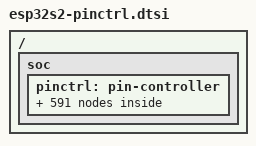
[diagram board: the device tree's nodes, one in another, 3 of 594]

/*
 * Copyright (c) 2022 Espressif Systems (Shanghai) Co., Ltd.
 *
 * SPDX-License-Identifier: Apache-2.0
 *
 * NOTE: Autogenerated file using esp_genpinctrl.py
 */

#include <dt-bindings/pinctrl/esp32-pinctrl.h>
#include <dt-bindings/pinctrl/esp32s2-gpio-sigmap.h>

/ {
	soc {
		pinctrl: pin-controller {

			/* I2C0's SCL pin states */
			i2c0_scl_gpio0: i2c0_scl_gpio0 {
				pinmux = <ESP32_PINMUX(0, ESP_I2CEXT0_SCL_IN, ESP_I2CEXT0_SCL_OUT)>;
				bias-pull-up;
				drive-open-drain;
				input-enable;
				output-high;
			};

			i2c0_scl_gpio1: i2c0_scl_gpio1 {
				pinmux = <ESP32_PINMUX(1, ESP_I2CEXT0_SCL_IN, ESP_I2CEXT0_SCL_OUT)>;
				bias-pull-up;
				drive-open-drain;
				input-enable;
				output-high;
			};

			i2c0_scl_gpio2: i2c0_scl_gpio2 {
				pinmux = <ESP32_PINMUX(2, ESP_I2CEXT0_SCL_IN, ESP_I2CEXT0_SCL_OUT)>;
				bias-pull-up;
				drive-open-drain;
				input-enable;
				output-high;
			};

			i2c0_scl_gpio3: i2c0_scl_gpio3 {
				pinmux = <ESP32_PINMUX(3, ESP_I2CEXT0_SCL_IN, ESP_I2CEXT0_SCL_OUT)>;
				bias-pull-up;
				drive-open-drain;
				input-enable;
				output-high;
			};

			i2c0_scl_gpio4: i2c0_scl_gpio4 {
				pinmux = <ESP32_PINMUX(4, ESP_I2CEXT0_SCL_IN, ESP_I2CEXT0_SCL_OUT)>;
				bias-pull-up;
				drive-open-drain;
				input-enable;
				output-high;
			};

			i2c0_scl_gpio5: i2c0_scl_gpio5 {
				pinmux = <ESP32_PINMUX(5, ESP_I2CEXT0_SCL_IN, ESP_I2CEXT0_SCL_OUT)>;
				bias-pull-up;
				drive-open-drain;
				input-enable;
				output-high;
			};

			i2c0_scl_gpio6: i2c0_scl_gpio6 {
				pinmux = <ESP32_PINMUX(6, ESP_I2CEXT0_SCL_IN, ESP_I2CEXT0_SCL_OUT)>;
				bias-pull-up;
				drive-open-drain;
				input-enable;
				output-high;
			};

			i2c0_scl_gpio7: i2c0_scl_gpio7 {
				pinmux = <ESP32_PINMUX(7, ESP_I2CEXT0_SCL_IN, ESP_I2CEXT0_SCL_OUT)>;
				bias-pull-up;
				drive-open-drain;
				input-enable;
				output-high;
			};

			i2c0_scl_gpio8: i2c0_scl_gpio8 {
				pinmux = <ESP32_PINMUX(8, ESP_I2CEXT0_SCL_IN, ESP_I2CEXT0_SCL_OUT)>;
				bias-pull-up;
				drive-open-drain;
				input-enable;
				output-high;
			};

			i2c0_scl_gpio9: i2c0_scl_gpio9 {
				pinmux = <ESP32_PINMUX(9, ESP_I2CEXT0_SCL_IN, ESP_I2CEXT0_SCL_OUT)>;
				bias-pull-up;
				drive-open-drain;
				input-enable;
				output-high;
			};

			i2c0_scl_gpio10: i2c0_scl_gpio10 {
				pinmux = <ESP32_PINMUX(10, ESP_I2CEXT0_SCL_IN, ESP_I2CEXT0_SCL_OUT)>;
				bias-pull-up;
				drive-open-drain;
				input-enable;
				output-high;
			};

			i2c0_scl_gpio11: i2c0_scl_gpio11 {
				pinmux = <ESP32_PINMUX(11, ESP_I2CEXT0_SCL_IN, ESP_I2CEXT0_SCL_OUT)>;
				bias-pull-up;
				drive-open-drain;
				input-enable;
				output-high;
			};

			i2c0_scl_gpio12: i2c0_scl_gpio12 {
				pinmux = <ESP32_PINMUX(12, ESP_I2CEXT0_SCL_IN, ESP_I2CEXT0_SCL_OUT)>;
				bias-pull-up;
				drive-open-drain;
				input-enable;
				output-high;
			};

			i2c0_scl_gpio13: i2c0_scl_gpio13 {
				pinmux = <ESP32_PINMUX(13, ESP_I2CEXT0_SCL_IN, ESP_I2CEXT0_SCL_OUT)>;
				bias-pull-up;
				drive-open-drain;
				input-enable;
				output-high;
			};

			i2c0_scl_gpio14: i2c0_scl_gpio14 {
				pinmux = <ESP32_PINMUX(14, ESP_I2CEXT0_SCL_IN, ESP_I2CEXT0_SCL_OUT)>;
				bias-pull-up;
				drive-open-drain;
				input-enable;
				output-high;
			};

			i2c0_scl_gpio15: i2c0_scl_gpio15 {
				pinmux = <ESP32_PINMUX(15, ESP_I2CEXT0_SCL_IN, ESP_I2CEXT0_SCL_OUT)>;
				bias-pull-up;
				drive-open-drain;
				input-enable;
				output-high;
			};

			i2c0_scl_gpio16: i2c0_scl_gpio16 {
				pinmux = <ESP32_PINMUX(16, ESP_I2CEXT0_SCL_IN, ESP_I2CEXT0_SCL_OUT)>;
				bias-pull-up;
				drive-open-drain;
				input-enable;
				output-high;
			};

			i2c0_scl_gpio17: i2c0_scl_gpio17 {
				pinmux = <ESP32_PINMUX(17, ESP_I2CEXT0_SCL_IN, ESP_I2CEXT0_SCL_OUT)>;
				bias-pull-up;
				drive-open-drain;
				input-enable;
				output-high;
			};

			i2c0_scl_gpio18: i2c0_scl_gpio18 {
				pinmux = <ESP32_PINMUX(18, ESP_I2CEXT0_SCL_IN, ESP_I2CEXT0_SCL_OUT)>;
				bias-pull-up;
				drive-open-drain;
				input-enable;
				output-high;
			};

			i2c0_scl_gpio19: i2c0_scl_gpio19 {
				pinmux = <ESP32_PINMUX(19, ESP_I2CEXT0_SCL_IN, ESP_I2CEXT0_SCL_OUT)>;
				bias-pull-up;
				drive-open-drain;
				input-enable;
				output-high;
			};

			i2c0_scl_gpio20: i2c0_scl_gpio20 {
				pinmux = <ESP32_PINMUX(20, ESP_I2CEXT0_SCL_IN, ESP_I2CEXT0_SCL_OUT)>;
				bias-pull-up;
				drive-open-drain;
				input-enable;
				output-high;
			};

			i2c0_scl_gpio21: i2c0_scl_gpio21 {
				pinmux = <ESP32_PINMUX(21, ESP_I2CEXT0_SCL_IN, ESP_I2CEXT0_SCL_OUT)>;
				bias-pull-up;
				drive-open-drain;
				input-enable;
				output-high;
			};

			i2c0_scl_gpio26: i2c0_scl_gpio26 {
				pinmux = <ESP32_PINMUX(26, ESP_I2CEXT0_SCL_IN, ESP_I2CEXT0_SCL_OUT)>;
				bias-pull-up;
				drive-open-drain;
				input-enable;
				output-high;
			};

			i2c0_scl_gpio27: i2c0_scl_gpio27 {
				pinmux = <ESP32_PINMUX(27, ESP_I2CEXT0_SCL_IN, ESP_I2CEXT0_SCL_OUT)>;
				bias-pull-up;
				drive-open-drain;
				input-enable;
				output-high;
			};

			i2c0_scl_gpio28: i2c0_scl_gpio28 {
				pinmux = <ESP32_PINMUX(28, ESP_I2CEXT0_SCL_IN, ESP_I2CEXT0_SCL_OUT)>;
				bias-pull-up;
				drive-open-drain;
				input-enable;
				output-high;
			};

			i2c0_scl_gpio29: i2c0_scl_gpio29 {
				pinmux = <ESP32_PINMUX(29, ESP_I2CEXT0_SCL_IN, ESP_I2CEXT0_SCL_OUT)>;
				bias-pull-up;
				drive-open-drain;
				input-enable;
				output-high;
			};

			i2c0_scl_gpio30: i2c0_scl_gpio30 {
				pinmux = <ESP32_PINMUX(30, ESP_I2CEXT0_SCL_IN, ESP_I2CEXT0_SCL_OUT)>;
				bias-pull-up;
				drive-open-drain;
				input-enable;
				output-high;
			};

			i2c0_scl_gpio31: i2c0_scl_gpio31 {
				pinmux = <ESP32_PINMUX(31, ESP_I2CEXT0_SCL_IN, ESP_I2CEXT0_SCL_OUT)>;
				bias-pull-up;
				drive-open-drain;
				input-enable;
				output-high;
			};

			i2c0_scl_gpio32: i2c0_scl_gpio32 {
				pinmux = <ESP32_PINMUX(32, ESP_I2CEXT0_SCL_IN, ESP_I2CEXT0_SCL_OUT)>;
				bias-pull-up;
				drive-open-drain;
				input-enable;
				output-high;
			};

			i2c0_scl_gpio33: i2c0_scl_gpio33 {
				pinmux = <ESP32_PINMUX(33, ESP_I2CEXT0_SCL_IN, ESP_I2CEXT0_SCL_OUT)>;
				bias-pull-up;
				drive-open-drain;
				input-enable;
				output-high;
			};

			i2c0_scl_gpio34: i2c0_scl_gpio34 {
				pinmux = <ESP32_PINMUX(34, ESP_I2CEXT0_SCL_IN, ESP_I2CEXT0_SCL_OUT)>;
				bias-pull-up;
				drive-open-drain;
				input-enable;
				output-high;
			};

			i2c0_scl_gpio35: i2c0_scl_gpio35 {
				pinmux = <ESP32_PINMUX(35, ESP_I2CEXT0_SCL_IN, ESP_I2CEXT0_SCL_OUT)>;
				bias-pull-up;
				drive-open-drain;
				input-enable;
				output-high;
			};

			i2c0_scl_gpio36: i2c0_scl_gpio36 {
				pinmux = <ESP32_PINMUX(36, ESP_I2CEXT0_SCL_IN, ESP_I2CEXT0_SCL_OUT)>;
				bias-pull-up;
				drive-open-drain;
				input-enable;
				output-high;
			};

			i2c0_scl_gpio37: i2c0_scl_gpio37 {
				pinmux = <ESP32_PINMUX(37, ESP_I2CEXT0_SCL_IN, ESP_I2CEXT0_SCL_OUT)>;
				bias-pull-up;
				drive-open-drain;
				input-enable;
				output-high;
			};

			i2c0_scl_gpio38: i2c0_scl_gpio38 {
				pinmux = <ESP32_PINMUX(38, ESP_I2CEXT0_SCL_IN, ESP_I2CEXT0_SCL_OUT)>;
				bias-pull-up;
				drive-open-drain;
				input-enable;
				output-high;
			};

			i2c0_scl_gpio39: i2c0_scl_gpio39 {
				pinmux = <ESP32_PINMUX(39, ESP_I2CEXT0_SCL_IN, ESP_I2CEXT0_SCL_OUT)>;
				bias-pull-up;
				drive-open-drain;
				input-enable;
				output-high;
			};

			i2c0_scl_gpio40: i2c0_scl_gpio40 {
				pinmux = <ESP32_PINMUX(40, ESP_I2CEXT0_SCL_IN, ESP_I2CEXT0_SCL_OUT)>;
				bias-pull-up;
				drive-open-drain;
				input-enable;
				output-high;
			};

			i2c0_scl_gpio41: i2c0_scl_gpio41 {
				pinmux = <ESP32_PINMUX(41, ESP_I2CEXT0_SCL_IN, ESP_I2CEXT0_SCL_OUT)>;
				bias-pull-up;
				drive-open-drain;
				input-enable;
				output-high;
			};

			i2c0_scl_gpio42: i2c0_scl_gpio42 {
				pinmux = <ESP32_PINMUX(42, ESP_I2CEXT0_SCL_IN, ESP_I2CEXT0_SCL_OUT)>;
				bias-pull-up;
				drive-open-drain;
				input-enable;
				output-high;
			};

			i2c0_scl_gpio43: i2c0_scl_gpio43 {
				pinmux = <ESP32_PINMUX(43, ESP_I2CEXT0_SCL_IN, ESP_I2CEXT0_SCL_OUT)>;
				bias-pull-up;
				drive-open-drain;
				input-enable;
				output-high;
			};

			i2c0_scl_gpio44: i2c0_scl_gpio44 {
				pinmux = <ESP32_PINMUX(44, ESP_I2CEXT0_SCL_IN, ESP_I2CEXT0_SCL_OUT)>;
				bias-pull-up;
				drive-open-drain;
				input-enable;
				output-high;
			};

			i2c0_scl_gpio45: i2c0_scl_gpio45 {
				pinmux = <ESP32_PINMUX(45, ESP_I2CEXT0_SCL_IN, ESP_I2CEXT0_SCL_OUT)>;
				bias-pull-up;
				drive-open-drain;
				input-enable;
				output-high;
			};

			/* I2C0's SDA pin states */
			i2c0_sda_gpio0: i2c0_sda_gpio0 {
				pinmux = <ESP32_PINMUX(0, ESP_I2CEXT0_SDA_IN, ESP_I2CEXT0_SDA_OUT)>;
				bias-pull-up;
				drive-open-drain;
				input-enable;
				output-high;
			};

			i2c0_sda_gpio1: i2c0_sda_gpio1 {
				pinmux = <ESP32_PINMUX(1, ESP_I2CEXT0_SDA_IN, ESP_I2CEXT0_SDA_OUT)>;
				bias-pull-up;
				drive-open-drain;
				input-enable;
				output-high;
			};

			i2c0_sda_gpio2: i2c0_sda_gpio2 {
				pinmux = <ESP32_PINMUX(2, ESP_I2CEXT0_SDA_IN, ESP_I2CEXT0_SDA_OUT)>;
				bias-pull-up;
				drive-open-drain;
				input-enable;
				output-high;
			};

			i2c0_sda_gpio3: i2c0_sda_gpio3 {
				pinmux = <ESP32_PINMUX(3, ESP_I2CEXT0_SDA_IN, ESP_I2CEXT0_SDA_OUT)>;
				bias-pull-up;
				drive-open-drain;
				input-enable;
				output-high;
			};

			i2c0_sda_gpio4: i2c0_sda_gpio4 {
				pinmux = <ESP32_PINMUX(4, ESP_I2CEXT0_SDA_IN, ESP_I2CEXT0_SDA_OUT)>;
				bias-pull-up;
				drive-open-drain;
				input-enable;
				output-high;
			};

			i2c0_sda_gpio5: i2c0_sda_gpio5 {
				pinmux = <ESP32_PINMUX(5, ESP_I2CEXT0_SDA_IN, ESP_I2CEXT0_SDA_OUT)>;
				bias-pull-up;
				drive-open-drain;
				input-enable;
				output-high;
			};

			i2c0_sda_gpio6: i2c0_sda_gpio6 {
				pinmux = <ESP32_PINMUX(6, ESP_I2CEXT0_SDA_IN, ESP_I2CEXT0_SDA_OUT)>;
				bias-pull-up;
				drive-open-drain;
				input-enable;
				output-high;
			};

			i2c0_sda_gpio7: i2c0_sda_gpio7 {
				pinmux = <ESP32_PINMUX(7, ESP_I2CEXT0_SDA_IN, ESP_I2CEXT0_SDA_OUT)>;
				bias-pull-up;
				drive-open-drain;
				input-enable;
				output-high;
			};

			i2c0_sda_gpio8: i2c0_sda_gpio8 {
				pinmux = <ESP32_PINMUX(8, ESP_I2CEXT0_SDA_IN, ESP_I2CEXT0_SDA_OUT)>;
				bias-pull-up;
				drive-open-drain;
				input-enable;
				output-high;
			};

			i2c0_sda_gpio9: i2c0_sda_gpio9 {
				pinmux = <ESP32_PINMUX(9, ESP_I2CEXT0_SDA_IN, ESP_I2CEXT0_SDA_OUT)>;
				bias-pull-up;
				drive-open-drain;
				input-enable;
				output-high;
			};

			i2c0_sda_gpio10: i2c0_sda_gpio10 {
				pinmux = <ESP32_PINMUX(10, ESP_I2CEXT0_SDA_IN, ESP_I2CEXT0_SDA_OUT)>;
				bias-pull-up;
				drive-open-drain;
				input-enable;
				output-high;
			};

			i2c0_sda_gpio11: i2c0_sda_gpio11 {
				pinmux = <ESP32_PINMUX(11, ESP_I2CEXT0_SDA_IN, ESP_I2CEXT0_SDA_OUT)>;
				bias-pull-up;
				drive-open-drain;
				input-enable;
				output-high;
			};

			i2c0_sda_gpio12: i2c0_sda_gpio12 {
				pinmux = <ESP32_PINMUX(12, ESP_I2CEXT0_SDA_IN, ESP_I2CEXT0_SDA_OUT)>;
				bias-pull-up;
				drive-open-drain;
				input-enable;
				output-high;
			};

			i2c0_sda_gpio13: i2c0_sda_gpio13 {
				pinmux = <ESP32_PINMUX(13, ESP_I2CEXT0_SDA_IN, ESP_I2CEXT0_SDA_OUT)>;
				bias-pull-up;
				drive-open-drain;
				input-enable;
				output-high;
			};

			i2c0_sda_gpio14: i2c0_sda_gpio14 {
				pinmux = <ESP32_PINMUX(14, ESP_I2CEXT0_SDA_IN, ESP_I2CEXT0_SDA_OUT)>;
				bias-pull-up;
				drive-open-drain;
				input-enable;
				output-high;
			};

			i2c0_sda_gpio15: i2c0_sda_gpio15 {
				pinmux = <ESP32_PINMUX(15, ESP_I2CEXT0_SDA_IN, ESP_I2CEXT0_SDA_OUT)>;
				bias-pull-up;
				drive-open-drain;
				input-enable;
				output-high;
			};

			i2c0_sda_gpio16: i2c0_sda_gpio16 {
				pinmux = <ESP32_PINMUX(16, ESP_I2CEXT0_SDA_IN, ESP_I2CEXT0_SDA_OUT)>;
				bias-pull-up;
				drive-open-drain;
				input-enable;
				output-high;
			};

			i2c0_sda_gpio17: i2c0_sda_gpio17 {
				pinmux = <ESP32_PINMUX(17, ESP_I2CEXT0_SDA_IN, ESP_I2CEXT0_SDA_OUT)>;
				bias-pull-up;
				drive-open-drain;
				input-enable;
				output-high;
			};

			i2c0_sda_gpio18: i2c0_sda_gpio18 {
				pinmux = <ESP32_PINMUX(18, ESP_I2CEXT0_SDA_IN, ESP_I2CEXT0_SDA_OUT)>;
				bias-pull-up;
				drive-open-drain;
				input-enable;
				output-high;
			};

			i2c0_sda_gpio19: i2c0_sda_gpio19 {
				pinmux = <ESP32_PINMUX(19, ESP_I2CEXT0_SDA_IN, ESP_I2CEXT0_SDA_OUT)>;
				bias-pull-up;
				drive-open-drain;
				input-enable;
				output-high;
			};

			i2c0_sda_gpio20: i2c0_sda_gpio20 {
				pinmux = <ESP32_PINMUX(20, ESP_I2CEXT0_SDA_IN, ESP_I2CEXT0_SDA_OUT)>;
				bias-pull-up;
				drive-open-drain;
				input-enable;
				output-high;
			};

			i2c0_sda_gpio21: i2c0_sda_gpio21 {
				pinmux = <ESP32_PINMUX(21, ESP_I2CEXT0_SDA_IN, ESP_I2CEXT0_SDA_OUT)>;
				bias-pull-up;
				drive-open-drain;
				input-enable;
				output-high;
			};

			i2c0_sda_gpio26: i2c0_sda_gpio26 {
				pinmux = <ESP32_PINMUX(26, ESP_I2CEXT0_SDA_IN, ESP_I2CEXT0_SDA_OUT)>;
				bias-pull-up;
				drive-open-drain;
				input-enable;
				output-high;
			};

			i2c0_sda_gpio27: i2c0_sda_gpio27 {
				pinmux = <ESP32_PINMUX(27, ESP_I2CEXT0_SDA_IN, ESP_I2CEXT0_SDA_OUT)>;
				bias-pull-up;
				drive-open-drain;
				input-enable;
				output-high;
			};

			i2c0_sda_gpio28: i2c0_sda_gpio28 {
				pinmux = <ESP32_PINMUX(28, ESP_I2CEXT0_SDA_IN, ESP_I2CEXT0_SDA_OUT)>;
				bias-pull-up;
				drive-open-drain;
				input-enable;
				output-high;
			};

			i2c0_sda_gpio29: i2c0_sda_gpio29 {
				pinmux = <ESP32_PINMUX(29, ESP_I2CEXT0_SDA_IN, ESP_I2CEXT0_SDA_OUT)>;
				bias-pull-up;
				drive-open-drain;
				input-enable;
				output-high;
			};

			i2c0_sda_gpio30: i2c0_sda_gpio30 {
				pinmux = <ESP32_PINMUX(30, ESP_I2CEXT0_SDA_IN, ESP_I2CEXT0_SDA_OUT)>;
				bias-pull-up;
				drive-open-drain;
				input-enable;
				output-high;
			};

			i2c0_sda_gpio31: i2c0_sda_gpio31 {
				pinmux = <ESP32_PINMUX(31, ESP_I2CEXT0_SDA_IN, ESP_I2CEXT0_SDA_OUT)>;
				bias-pull-up;
				drive-open-drain;
				input-enable;
				output-high;
			};

			i2c0_sda_gpio32: i2c0_sda_gpio32 {
				pinmux = <ESP32_PINMUX(32, ESP_I2CEXT0_SDA_IN, ESP_I2CEXT0_SDA_OUT)>;
				bias-pull-up;
				drive-open-drain;
				input-enable;
				output-high;
			};

			i2c0_sda_gpio33: i2c0_sda_gpio33 {
				pinmux = <ESP32_PINMUX(33, ESP_I2CEXT0_SDA_IN, ESP_I2CEXT0_SDA_OUT)>;
				bias-pull-up;
				drive-open-drain;
				input-enable;
				output-high;
			};

			i2c0_sda_gpio34: i2c0_sda_gpio34 {
				pinmux = <ESP32_PINMUX(34, ESP_I2CEXT0_SDA_IN, ESP_I2CEXT0_SDA_OUT)>;
				bias-pull-up;
				drive-open-drain;
				input-enable;
				output-high;
			};

			i2c0_sda_gpio35: i2c0_sda_gpio35 {
				pinmux = <ESP32_PINMUX(35, ESP_I2CEXT0_SDA_IN, ESP_I2CEXT0_SDA_OUT)>;
				bias-pull-up;
				drive-open-drain;
				input-enable;
				output-high;
			};

			i2c0_sda_gpio36: i2c0_sda_gpio36 {
				pinmux = <ESP32_PINMUX(36, ESP_I2CEXT0_SDA_IN, ESP_I2CEXT0_SDA_OUT)>;
				bias-pull-up;
				drive-open-drain;
				input-enable;
				output-high;
			};

			i2c0_sda_gpio37: i2c0_sda_gpio37 {
				pinmux = <ESP32_PINMUX(37, ESP_I2CEXT0_SDA_IN, ESP_I2CEXT0_SDA_OUT)>;
				bias-pull-up;
				drive-open-drain;
				input-enable;
				output-high;
			};

			i2c0_sda_gpio38: i2c0_sda_gpio38 {
				pinmux = <ESP32_PINMUX(38, ESP_I2CEXT0_SDA_IN, ESP_I2CEXT0_SDA_OUT)>;
				bias-pull-up;
				drive-open-drain;
				input-enable;
				output-high;
			};

			i2c0_sda_gpio39: i2c0_sda_gpio39 {
				pinmux = <ESP32_PINMUX(39, ESP_I2CEXT0_SDA_IN, ESP_I2CEXT0_SDA_OUT)>;
				bias-pull-up;
				drive-open-drain;
				input-enable;
				output-high;
			};

			i2c0_sda_gpio40: i2c0_sda_gpio40 {
				pinmux = <ESP32_PINMUX(40, ESP_I2CEXT0_SDA_IN, ESP_I2CEXT0_SDA_OUT)>;
				bias-pull-up;
				drive-open-drain;
				input-enable;
				output-high;
			};

			i2c0_sda_gpio41: i2c0_sda_gpio41 {
				pinmux = <ESP32_PINMUX(41, ESP_I2CEXT0_SDA_IN, ESP_I2CEXT0_SDA_OUT)>;
				bias-pull-up;
				drive-open-drain;
				input-enable;
				output-high;
			};

			i2c0_sda_gpio42: i2c0_sda_gpio42 {
				pinmux = <ESP32_PINMUX(42, ESP_I2CEXT0_SDA_IN, ESP_I2CEXT0_SDA_OUT)>;
				bias-pull-up;
				drive-open-drain;
				input-enable;
				output-high;
			};

			i2c0_sda_gpio43: i2c0_sda_gpio43 {
				pinmux = <ESP32_PINMUX(43, ESP_I2CEXT0_SDA_IN, ESP_I2CEXT0_SDA_OUT)>;
				bias-pull-up;
				drive-open-drain;
				input-enable;
				output-high;
			};

			i2c0_sda_gpio44: i2c0_sda_gpio44 {
				pinmux = <ESP32_PINMUX(44, ESP_I2CEXT0_SDA_IN, ESP_I2CEXT0_SDA_OUT)>;
				bias-pull-up;
				drive-open-drain;
				input-enable;
				output-high;
			};

			i2c0_sda_gpio45: i2c0_sda_gpio45 {
				pinmux = <ESP32_PINMUX(45, ESP_I2CEXT0_SDA_IN, ESP_I2CEXT0_SDA_OUT)>;
				bias-pull-up;
				drive-open-drain;
				input-enable;
				output-high;
			};

			/* I2C1's SCL pin states */
			i2c1_scl_gpio0: i2c1_scl_gpio0 {
				pinmux = <ESP32_PINMUX(0, ESP_I2CEXT1_SCL_IN, ESP_I2CEXT1_SCL_OUT)>;
				bias-pull-up;
				drive-open-drain;
				input-enable;
				output-high;
			};

			i2c1_scl_gpio1: i2c1_scl_gpio1 {
				pinmux = <ESP32_PINMUX(1, ESP_I2CEXT1_SCL_IN, ESP_I2CEXT1_SCL_OUT)>;
				bias-pull-up;
				drive-open-drain;
				input-enable;
				output-high;
			};

			i2c1_scl_gpio2: i2c1_scl_gpio2 {
				pinmux = <ESP32_PINMUX(2, ESP_I2CEXT1_SCL_IN, ESP_I2CEXT1_SCL_OUT)>;
				bias-pull-up;
				drive-open-drain;
				input-enable;
				output-high;
			};

			i2c1_scl_gpio3: i2c1_scl_gpio3 {
				pinmux = <ESP32_PINMUX(3, ESP_I2CEXT1_SCL_IN, ESP_I2CEXT1_SCL_OUT)>;
				bias-pull-up;
				drive-open-drain;
				input-enable;
				output-high;
			};

			i2c1_scl_gpio4: i2c1_scl_gpio4 {
				pinmux = <ESP32_PINMUX(4, ESP_I2CEXT1_SCL_IN, ESP_I2CEXT1_SCL_OUT)>;
				bias-pull-up;
				drive-open-drain;
				input-enable;
				output-high;
			};

			i2c1_scl_gpio5: i2c1_scl_gpio5 {
				pinmux = <ESP32_PINMUX(5, ESP_I2CEXT1_SCL_IN, ESP_I2CEXT1_SCL_OUT)>;
				bias-pull-up;
				drive-open-drain;
				input-enable;
				output-high;
			};

			i2c1_scl_gpio6: i2c1_scl_gpio6 {
				pinmux = <ESP32_PINMUX(6, ESP_I2CEXT1_SCL_IN, ESP_I2CEXT1_SCL_OUT)>;
				bias-pull-up;
				drive-open-drain;
				input-enable;
				output-high;
			};

			i2c1_scl_gpio7: i2c1_scl_gpio7 {
				pinmux = <ESP32_PINMUX(7, ESP_I2CEXT1_SCL_IN, ESP_I2CEXT1_SCL_OUT)>;
				bias-pull-up;
				drive-open-drain;
				input-enable;
				output-high;
			};

			i2c1_scl_gpio8: i2c1_scl_gpio8 {
				pinmux = <ESP32_PINMUX(8, ESP_I2CEXT1_SCL_IN, ESP_I2CEXT1_SCL_OUT)>;
				bias-pull-up;
				drive-open-drain;
				input-enable;
				output-high;
			};

			i2c1_scl_gpio9: i2c1_scl_gpio9 {
				pinmux = <ESP32_PINMUX(9, ESP_I2CEXT1_SCL_IN, ESP_I2CEXT1_SCL_OUT)>;
				bias-pull-up;
				drive-open-drain;
				input-enable;
				output-high;
			};

			i2c1_scl_gpio10: i2c1_scl_gpio10 {
				pinmux = <ESP32_PINMUX(10, ESP_I2CEXT1_SCL_IN, ESP_I2CEXT1_SCL_OUT)>;
				bias-pull-up;
				drive-open-drain;
				input-enable;
				output-high;
			};

			i2c1_scl_gpio11: i2c1_scl_gpio11 {
				pinmux = <ESP32_PINMUX(11, ESP_I2CEXT1_SCL_IN, ESP_I2CEXT1_SCL_OUT)>;
				bias-pull-up;
				drive-open-drain;
				input-enable;
				output-high;
			};

			i2c1_scl_gpio12: i2c1_scl_gpio12 {
				pinmux = <ESP32_PINMUX(12, ESP_I2CEXT1_SCL_IN, ESP_I2CEXT1_SCL_OUT)>;
				bias-pull-up;
				drive-open-drain;
				input-enable;
				output-high;
			};

			i2c1_scl_gpio13: i2c1_scl_gpio13 {
				pinmux = <ESP32_PINMUX(13, ESP_I2CEXT1_SCL_IN, ESP_I2CEXT1_SCL_OUT)>;
				bias-pull-up;
				drive-open-drain;
				input-enable;
				output-high;
			};

			i2c1_scl_gpio14: i2c1_scl_gpio14 {
				pinmux = <ESP32_PINMUX(14, ESP_I2CEXT1_SCL_IN, ESP_I2CEXT1_SCL_OUT)>;
				bias-pull-up;
				drive-open-drain;
				input-enable;
				output-high;
			};

			i2c1_scl_gpio15: i2c1_scl_gpio15 {
				pinmux = <ESP32_PINMUX(15, ESP_I2CEXT1_SCL_IN, ESP_I2CEXT1_SCL_OUT)>;
				bias-pull-up;
				drive-open-drain;
				input-enable;
				output-high;
			};

			i2c1_scl_gpio16: i2c1_scl_gpio16 {
				pinmux = <ESP32_PINMUX(16, ESP_I2CEXT1_SCL_IN, ESP_I2CEXT1_SCL_OUT)>;
				bias-pull-up;
				drive-open-drain;
				input-enable;
				output-high;
			};

			i2c1_scl_gpio17: i2c1_scl_gpio17 {
				pinmux = <ESP32_PINMUX(17, ESP_I2CEXT1_SCL_IN, ESP_I2CEXT1_SCL_OUT)>;
				bias-pull-up;
				drive-open-drain;
				input-enable;
				output-high;
			};

			i2c1_scl_gpio18: i2c1_scl_gpio18 {
				pinmux = <ESP32_PINMUX(18, ESP_I2CEXT1_SCL_IN, ESP_I2CEXT1_SCL_OUT)>;
				bias-pull-up;
				drive-open-drain;
				input-enable;
				output-high;
			};

			i2c1_scl_gpio19: i2c1_scl_gpio19 {
				pinmux = <ESP32_PINMUX(19, ESP_I2CEXT1_SCL_IN, ESP_I2CEXT1_SCL_OUT)>;
				bias-pull-up;
				drive-open-drain;
				input-enable;
				output-high;
			};

			i2c1_scl_gpio20: i2c1_scl_gpio20 {
				pinmux = <ESP32_PINMUX(20, ESP_I2CEXT1_SCL_IN, ESP_I2CEXT1_SCL_OUT)>;
				bias-pull-up;
				drive-open-drain;
				input-enable;
				output-high;
			};

			i2c1_scl_gpio21: i2c1_scl_gpio21 {
				pinmux = <ESP32_PINMUX(21, ESP_I2CEXT1_SCL_IN, ESP_I2CEXT1_SCL_OUT)>;
				bias-pull-up;
				drive-open-drain;
				input-enable;
				output-high;
			};

			i2c1_scl_gpio26: i2c1_scl_gpio26 {
				pinmux = <ESP32_PINMUX(26, ESP_I2CEXT1_SCL_IN, ESP_I2CEXT1_SCL_OUT)>;
				bias-pull-up;
				drive-open-drain;
				input-enable;
				output-high;
			};

			i2c1_scl_gpio27: i2c1_scl_gpio27 {
				pinmux = <ESP32_PINMUX(27, ESP_I2CEXT1_SCL_IN, ESP_I2CEXT1_SCL_OUT)>;
				bias-pull-up;
				drive-open-drain;
				input-enable;
				output-high;
			};

			i2c1_scl_gpio28: i2c1_scl_gpio28 {
				pinmux = <ESP32_PINMUX(28, ESP_I2CEXT1_SCL_IN, ESP_I2CEXT1_SCL_OUT)>;
				bias-pull-up;
				drive-open-drain;
				input-enable;
				output-high;
			};

			i2c1_scl_gpio29: i2c1_scl_gpio29 {
				pinmux = <ESP32_PINMUX(29, ESP_I2CEXT1_SCL_IN, ESP_I2CEXT1_SCL_OUT)>;
				bias-pull-up;
				drive-open-drain;
				input-enable;
				output-high;
			};

			i2c1_scl_gpio30: i2c1_scl_gpio30 {
				pinmux = <ESP32_PINMUX(30, ESP_I2CEXT1_SCL_IN, ESP_I2CEXT1_SCL_OUT)>;
				bias-pull-up;
				drive-open-drain;
				input-enable;
				output-high;
			};

			i2c1_scl_gpio31: i2c1_scl_gpio31 {
				pinmux = <ESP32_PINMUX(31, ESP_I2CEXT1_SCL_IN, ESP_I2CEXT1_SCL_OUT)>;
				bias-pull-up;
				drive-open-drain;
				input-enable;
				output-high;
			};

			i2c1_scl_gpio32: i2c1_scl_gpio32 {
				pinmux = <ESP32_PINMUX(32, ESP_I2CEXT1_SCL_IN, ESP_I2CEXT1_SCL_OUT)>;
				bias-pull-up;
				drive-open-drain;
				input-enable;
				output-high;
			};

			i2c1_scl_gpio33: i2c1_scl_gpio33 {
				pinmux = <ESP32_PINMUX(33, ESP_I2CEXT1_SCL_IN, ESP_I2CEXT1_SCL_OUT)>;
				bias-pull-up;
				drive-open-drain;
				input-enable;
				output-high;
			};

			i2c1_scl_gpio34: i2c1_scl_gpio34 {
				pinmux = <ESP32_PINMUX(34, ESP_I2CEXT1_SCL_IN, ESP_I2CEXT1_SCL_OUT)>;
				bias-pull-up;
				drive-open-drain;
				input-enable;
				output-high;
			};

			i2c1_scl_gpio35: i2c1_scl_gpio35 {
				pinmux = <ESP32_PINMUX(35, ESP_I2CEXT1_SCL_IN, ESP_I2CEXT1_SCL_OUT)>;
				bias-pull-up;
				drive-open-drain;
				input-enable;
				output-high;
			};

			i2c1_scl_gpio36: i2c1_scl_gpio36 {
				pinmux = <ESP32_PINMUX(36, ESP_I2CEXT1_SCL_IN, ESP_I2CEXT1_SCL_OUT)>;
				bias-pull-up;
				drive-open-drain;
				input-enable;
				output-high;
			};

			i2c1_scl_gpio37: i2c1_scl_gpio37 {
				pinmux = <ESP32_PINMUX(37, ESP_I2CEXT1_SCL_IN, ESP_I2CEXT1_SCL_OUT)>;
				bias-pull-up;
				drive-open-drain;
				input-enable;
				output-high;
			};

			i2c1_scl_gpio38: i2c1_scl_gpio38 {
				pinmux = <ESP32_PINMUX(38, ESP_I2CEXT1_SCL_IN, ESP_I2CEXT1_SCL_OUT)>;
				bias-pull-up;
				drive-open-drain;
				input-enable;
				output-high;
			};

			i2c1_scl_gpio39: i2c1_scl_gpio39 {
				pinmux = <ESP32_PINMUX(39, ESP_I2CEXT1_SCL_IN, ESP_I2CEXT1_SCL_OUT)>;
				bias-pull-up;
				drive-open-drain;
				input-enable;
				output-high;
			};

			i2c1_scl_gpio40: i2c1_scl_gpio40 {
				pinmux = <ESP32_PINMUX(40, ESP_I2CEXT1_SCL_IN, ESP_I2CEXT1_SCL_OUT)>;
				bias-pull-up;
				drive-open-drain;
				input-enable;
				output-high;
			};

			i2c1_scl_gpio41: i2c1_scl_gpio41 {
				pinmux = <ESP32_PINMUX(41, ESP_I2CEXT1_SCL_IN, ESP_I2CEXT1_SCL_OUT)>;
				bias-pull-up;
				drive-open-drain;
				input-enable;
				output-high;
			};

			i2c1_scl_gpio42: i2c1_scl_gpio42 {
				pinmux = <ESP32_PINMUX(42, ESP_I2CEXT1_SCL_IN, ESP_I2CEXT1_SCL_OUT)>;
				bias-pull-up;
				drive-open-drain;
				input-enable;
				output-high;
			};

			i2c1_scl_gpio43: i2c1_scl_gpio43 {
				pinmux = <ESP32_PINMUX(43, ESP_I2CEXT1_SCL_IN, ESP_I2CEXT1_SCL_OUT)>;
				bias-pull-up;
				drive-open-drain;
				input-enable;
				output-high;
			};

			i2c1_scl_gpio44: i2c1_scl_gpio44 {
				pinmux = <ESP32_PINMUX(44, ESP_I2CEXT1_SCL_IN, ESP_I2CEXT1_SCL_OUT)>;
				bias-pull-up;
				drive-open-drain;
				input-enable;
				output-high;
			};

			i2c1_scl_gpio45: i2c1_scl_gpio45 {
				pinmux = <ESP32_PINMUX(45, ESP_I2CEXT1_SCL_IN, ESP_I2CEXT1_SCL_OUT)>;
				bias-pull-up;
				drive-open-drain;
				input-enable;
				output-high;
			};

			/* I2C1's SDA pin states */
			i2c1_sda_gpio0: i2c1_sda_gpio0 {
				pinmux = <ESP32_PINMUX(0, ESP_I2CEXT1_SDA_IN, ESP_I2CEXT1_SDA_OUT)>;
				bias-pull-up;
				drive-open-drain;
				input-enable;
				output-high;
			};

			i2c1_sda_gpio1: i2c1_sda_gpio1 {
				pinmux = <ESP32_PINMUX(1, ESP_I2CEXT1_SDA_IN, ESP_I2CEXT1_SDA_OUT)>;
				bias-pull-up;
				drive-open-drain;
				input-enable;
				output-high;
			};

			i2c1_sda_gpio2: i2c1_sda_gpio2 {
				pinmux = <ESP32_PINMUX(2, ESP_I2CEXT1_SDA_IN, ESP_I2CEXT1_SDA_OUT)>;
				bias-pull-up;
				drive-open-drain;
				input-enable;
				output-high;
			};

			i2c1_sda_gpio3: i2c1_sda_gpio3 {
				pinmux = <ESP32_PINMUX(3, ESP_I2CEXT1_SDA_IN, ESP_I2CEXT1_SDA_OUT)>;
				bias-pull-up;
				drive-open-drain;
				input-enable;
				output-high;
			};

			i2c1_sda_gpio4: i2c1_sda_gpio4 {
				pinmux = <ESP32_PINMUX(4, ESP_I2CEXT1_SDA_IN, ESP_I2CEXT1_SDA_OUT)>;
				bias-pull-up;
				drive-open-drain;
				input-enable;
				output-high;
			};

			i2c1_sda_gpio5: i2c1_sda_gpio5 {
				pinmux = <ESP32_PINMUX(5, ESP_I2CEXT1_SDA_IN, ESP_I2CEXT1_SDA_OUT)>;
				bias-pull-up;
				drive-open-drain;
				input-enable;
				output-high;
			};

			i2c1_sda_gpio6: i2c1_sda_gpio6 {
				pinmux = <ESP32_PINMUX(6, ESP_I2CEXT1_SDA_IN, ESP_I2CEXT1_SDA_OUT)>;
				bias-pull-up;
				drive-open-drain;
				input-enable;
				output-high;
			};

			i2c1_sda_gpio7: i2c1_sda_gpio7 {
				pinmux = <ESP32_PINMUX(7, ESP_I2CEXT1_SDA_IN, ESP_I2CEXT1_SDA_OUT)>;
				bias-pull-up;
				drive-open-drain;
				input-enable;
				output-high;
			};

			i2c1_sda_gpio8: i2c1_sda_gpio8 {
				pinmux = <ESP32_PINMUX(8, ESP_I2CEXT1_SDA_IN, ESP_I2CEXT1_SDA_OUT)>;
				bias-pull-up;
				drive-open-drain;
				input-enable;
				output-high;
			};

			i2c1_sda_gpio9: i2c1_sda_gpio9 {
				pinmux = <ESP32_PINMUX(9, ESP_I2CEXT1_SDA_IN, ESP_I2CEXT1_SDA_OUT)>;
				bias-pull-up;
				drive-open-drain;
				input-enable;
				output-high;
			};

			i2c1_sda_gpio10: i2c1_sda_gpio10 {
				pinmux = <ESP32_PINMUX(10, ESP_I2CEXT1_SDA_IN, ESP_I2CEXT1_SDA_OUT)>;
				bias-pull-up;
				drive-open-drain;
				input-enable;
				output-high;
			};

			i2c1_sda_gpio11: i2c1_sda_gpio11 {
				pinmux = <ESP32_PINMUX(11, ESP_I2CEXT1_SDA_IN, ESP_I2CEXT1_SDA_OUT)>;
				bias-pull-up;
				drive-open-drain;
				input-enable;
				output-high;
			};

			i2c1_sda_gpio12: i2c1_sda_gpio12 {
				pinmux = <ESP32_PINMUX(12, ESP_I2CEXT1_SDA_IN, ESP_I2CEXT1_SDA_OUT)>;
				bias-pull-up;
				drive-open-drain;
				input-enable;
				output-high;
			};

			i2c1_sda_gpio13: i2c1_sda_gpio13 {
				pinmux = <ESP32_PINMUX(13, ESP_I2CEXT1_SDA_IN, ESP_I2CEXT1_SDA_OUT)>;
				bias-pull-up;
				drive-open-drain;
				input-enable;
				output-high;
			};

			i2c1_sda_gpio14: i2c1_sda_gpio14 {
				pinmux = <ESP32_PINMUX(14, ESP_I2CEXT1_SDA_IN, ESP_I2CEXT1_SDA_OUT)>;
				bias-pull-up;
				drive-open-drain;
				input-enable;
				output-high;
			};

			i2c1_sda_gpio15: i2c1_sda_gpio15 {
				pinmux = <ESP32_PINMUX(15, ESP_I2CEXT1_SDA_IN, ESP_I2CEXT1_SDA_OUT)>;
				bias-pull-up;
				drive-open-drain;
				input-enable;
				output-high;
			};

			i2c1_sda_gpio16: i2c1_sda_gpio16 {
				pinmux = <ESP32_PINMUX(16, ESP_I2CEXT1_SDA_IN, ESP_I2CEXT1_SDA_OUT)>;
				bias-pull-up;
				drive-open-drain;
				input-enable;
				output-high;
			};

			i2c1_sda_gpio17: i2c1_sda_gpio17 {
				pinmux = <ESP32_PINMUX(17, ESP_I2CEXT1_SDA_IN, ESP_I2CEXT1_SDA_OUT)>;
				bias-pull-up;
				drive-open-drain;
				input-enable;
				output-high;
			};

			i2c1_sda_gpio18: i2c1_sda_gpio18 {
				pinmux = <ESP32_PINMUX(18, ESP_I2CEXT1_SDA_IN, ESP_I2CEXT1_SDA_OUT)>;
				bias-pull-up;
				drive-open-drain;
				input-enable;
				output-high;
			};

			i2c1_sda_gpio19: i2c1_sda_gpio19 {
				pinmux = <ESP32_PINMUX(19, ESP_I2CEXT1_SDA_IN, ESP_I2CEXT1_SDA_OUT)>;
				bias-pull-up;
				drive-open-drain;
				input-enable;
				output-high;
			};

			i2c1_sda_gpio20: i2c1_sda_gpio20 {
				pinmux = <ESP32_PINMUX(20, ESP_I2CEXT1_SDA_IN, ESP_I2CEXT1_SDA_OUT)>;
				bias-pull-up;
				drive-open-drain;
				input-enable;
				output-high;
			};

			i2c1_sda_gpio21: i2c1_sda_gpio21 {
				pinmux = <ESP32_PINMUX(21, ESP_I2CEXT1_SDA_IN, ESP_I2CEXT1_SDA_OUT)>;
				bias-pull-up;
				drive-open-drain;
				input-enable;
				output-high;
			};

			i2c1_sda_gpio26: i2c1_sda_gpio26 {
				pinmux = <ESP32_PINMUX(26, ESP_I2CEXT1_SDA_IN, ESP_I2CEXT1_SDA_OUT)>;
				bias-pull-up;
				drive-open-drain;
				input-enable;
				output-high;
			};

			i2c1_sda_gpio27: i2c1_sda_gpio27 {
				pinmux = <ESP32_PINMUX(27, ESP_I2CEXT1_SDA_IN, ESP_I2CEXT1_SDA_OUT)>;
				bias-pull-up;
				drive-open-drain;
				input-enable;
				output-high;
			};

			i2c1_sda_gpio28: i2c1_sda_gpio28 {
				pinmux = <ESP32_PINMUX(28, ESP_I2CEXT1_SDA_IN, ESP_I2CEXT1_SDA_OUT)>;
				bias-pull-up;
				drive-open-drain;
				input-enable;
				output-high;
			};

			i2c1_sda_gpio29: i2c1_sda_gpio29 {
				pinmux = <ESP32_PINMUX(29, ESP_I2CEXT1_SDA_IN, ESP_I2CEXT1_SDA_OUT)>;
				bias-pull-up;
				drive-open-drain;
				input-enable;
				output-high;
			};

			i2c1_sda_gpio30: i2c1_sda_gpio30 {
				pinmux = <ESP32_PINMUX(30, ESP_I2CEXT1_SDA_IN, ESP_I2CEXT1_SDA_OUT)>;
				bias-pull-up;
				drive-open-drain;
				input-enable;
				output-high;
			};

			i2c1_sda_gpio31: i2c1_sda_gpio31 {
				pinmux = <ESP32_PINMUX(31, ESP_I2CEXT1_SDA_IN, ESP_I2CEXT1_SDA_OUT)>;
				bias-pull-up;
				drive-open-drain;
				input-enable;
				output-high;
			};

			i2c1_sda_gpio32: i2c1_sda_gpio32 {
				pinmux = <ESP32_PINMUX(32, ESP_I2CEXT1_SDA_IN, ESP_I2CEXT1_SDA_OUT)>;
				bias-pull-up;
				drive-open-drain;
				input-enable;
				output-high;
			};

			i2c1_sda_gpio33: i2c1_sda_gpio33 {
				pinmux = <ESP32_PINMUX(33, ESP_I2CEXT1_SDA_IN, ESP_I2CEXT1_SDA_OUT)>;
				bias-pull-up;
				drive-open-drain;
				input-enable;
				output-high;
			};

			i2c1_sda_gpio34: i2c1_sda_gpio34 {
				pinmux = <ESP32_PINMUX(34, ESP_I2CEXT1_SDA_IN, ESP_I2CEXT1_SDA_OUT)>;
				bias-pull-up;
				drive-open-drain;
				input-enable;
				output-high;
			};

			i2c1_sda_gpio35: i2c1_sda_gpio35 {
				pinmux = <ESP32_PINMUX(35, ESP_I2CEXT1_SDA_IN, ESP_I2CEXT1_SDA_OUT)>;
				bias-pull-up;
				drive-open-drain;
				input-enable;
				output-high;
			};

			i2c1_sda_gpio36: i2c1_sda_gpio36 {
				pinmux = <ESP32_PINMUX(36, ESP_I2CEXT1_SDA_IN, ESP_I2CEXT1_SDA_OUT)>;
				bias-pull-up;
				drive-open-drain;
				input-enable;
				output-high;
			};

			i2c1_sda_gpio37: i2c1_sda_gpio37 {
				pinmux = <ESP32_PINMUX(37, ESP_I2CEXT1_SDA_IN, ESP_I2CEXT1_SDA_OUT)>;
				bias-pull-up;
				drive-open-drain;
				input-enable;
				output-high;
			};

			i2c1_sda_gpio38: i2c1_sda_gpio38 {
				pinmux = <ESP32_PINMUX(38, ESP_I2CEXT1_SDA_IN, ESP_I2CEXT1_SDA_OUT)>;
				bias-pull-up;
				drive-open-drain;
				input-enable;
				output-high;
			};

			i2c1_sda_gpio39: i2c1_sda_gpio39 {
				pinmux = <ESP32_PINMUX(39, ESP_I2CEXT1_SDA_IN, ESP_I2CEXT1_SDA_OUT)>;
				bias-pull-up;
				drive-open-drain;
				input-enable;
				output-high;
			};

			i2c1_sda_gpio40: i2c1_sda_gpio40 {
				pinmux = <ESP32_PINMUX(40, ESP_I2CEXT1_SDA_IN, ESP_I2CEXT1_SDA_OUT)>;
				bias-pull-up;
				drive-open-drain;
				input-enable;
				output-high;
			};

			i2c1_sda_gpio41: i2c1_sda_gpio41 {
				pinmux = <ESP32_PINMUX(41, ESP_I2CEXT1_SDA_IN, ESP_I2CEXT1_SDA_OUT)>;
				bias-pull-up;
				drive-open-drain;
				input-enable;
				output-high;
			};

			i2c1_sda_gpio42: i2c1_sda_gpio42 {
				pinmux = <ESP32_PINMUX(42, ESP_I2CEXT1_SDA_IN, ESP_I2CEXT1_SDA_OUT)>;
				bias-pull-up;
				drive-open-drain;
				input-enable;
				output-high;
			};

			i2c1_sda_gpio43: i2c1_sda_gpio43 {
				pinmux = <ESP32_PINMUX(43, ESP_I2CEXT1_SDA_IN, ESP_I2CEXT1_SDA_OUT)>;
				bias-pull-up;
				drive-open-drain;
				input-enable;
				output-high;
			};

			i2c1_sda_gpio44: i2c1_sda_gpio44 {
				pinmux = <ESP32_PINMUX(44, ESP_I2CEXT1_SDA_IN, ESP_I2CEXT1_SDA_OUT)>;
				bias-pull-up;
				drive-open-drain;
				input-enable;
				output-high;
			};

			i2c1_sda_gpio45: i2c1_sda_gpio45 {
				pinmux = <ESP32_PINMUX(45, ESP_I2CEXT1_SDA_IN, ESP_I2CEXT1_SDA_OUT)>;
				bias-pull-up;
				drive-open-drain;
				input-enable;
				output-high;
			};

			/* SPIM2's CSEL pin states */
			spim2_csel_gpio0: spim2_csel_gpio0 {
				pinmux = <ESP32_PINMUX(0, ESP_NOSIG, ESP_FSPICS0_OUT)>;
				output-enable;
			};

			spim2_csel_gpio1: spim2_csel_gpio1 {
				pinmux = <ESP32_PINMUX(1, ESP_NOSIG, ESP_FSPICS0_OUT)>;
				output-enable;
			};

			spim2_csel_gpio2: spim2_csel_gpio2 {
				pinmux = <ESP32_PINMUX(2, ESP_NOSIG, ESP_FSPICS0_OUT)>;
				output-enable;
			};

			spim2_csel_gpio3: spim2_csel_gpio3 {
				pinmux = <ESP32_PINMUX(3, ESP_NOSIG, ESP_FSPICS0_OUT)>;
				output-enable;
			};

			spim2_csel_gpio4: spim2_csel_gpio4 {
				pinmux = <ESP32_PINMUX(4, ESP_NOSIG, ESP_FSPICS0_OUT)>;
				output-enable;
			};

			spim2_csel_gpio5: spim2_csel_gpio5 {
				pinmux = <ESP32_PINMUX(5, ESP_NOSIG, ESP_FSPICS0_OUT)>;
				output-enable;
			};

			spim2_csel_gpio6: spim2_csel_gpio6 {
				pinmux = <ESP32_PINMUX(6, ESP_NOSIG, ESP_FSPICS0_OUT)>;
				output-enable;
			};

			spim2_csel_gpio7: spim2_csel_gpio7 {
				pinmux = <ESP32_PINMUX(7, ESP_NOSIG, ESP_FSPICS0_OUT)>;
				output-enable;
			};

			spim2_csel_gpio8: spim2_csel_gpio8 {
				pinmux = <ESP32_PINMUX(8, ESP_NOSIG, ESP_FSPICS0_OUT)>;
				output-enable;
			};

			spim2_csel_gpio9: spim2_csel_gpio9 {
				pinmux = <ESP32_PINMUX(9, ESP_NOSIG, ESP_FSPICS0_OUT)>;
				output-enable;
			};

			spim2_csel_gpio10: spim2_csel_gpio10 {
				pinmux = <ESP32_PINMUX(10, ESP_NOSIG, ESP_FSPICS0_OUT)>;
				output-enable;
			};

			spim2_csel_gpio11: spim2_csel_gpio11 {
				pinmux = <ESP32_PINMUX(11, ESP_NOSIG, ESP_FSPICS0_OUT)>;
				output-enable;
			};

			spim2_csel_gpio12: spim2_csel_gpio12 {
				pinmux = <ESP32_PINMUX(12, ESP_NOSIG, ESP_FSPICS0_OUT)>;
				output-enable;
			};

			spim2_csel_gpio13: spim2_csel_gpio13 {
				pinmux = <ESP32_PINMUX(13, ESP_NOSIG, ESP_FSPICS0_OUT)>;
				output-enable;
			};

			spim2_csel_gpio14: spim2_csel_gpio14 {
				pinmux = <ESP32_PINMUX(14, ESP_NOSIG, ESP_FSPICS0_OUT)>;
				output-enable;
			};

			spim2_csel_gpio15: spim2_csel_gpio15 {
				pinmux = <ESP32_PINMUX(15, ESP_NOSIG, ESP_FSPICS0_OUT)>;
				output-enable;
			};

			spim2_csel_gpio16: spim2_csel_gpio16 {
				pinmux = <ESP32_PINMUX(16, ESP_NOSIG, ESP_FSPICS0_OUT)>;
				output-enable;
			};

			spim2_csel_gpio17: spim2_csel_gpio17 {
				pinmux = <ESP32_PINMUX(17, ESP_NOSIG, ESP_FSPICS0_OUT)>;
				output-enable;
			};

			spim2_csel_gpio18: spim2_csel_gpio18 {
				pinmux = <ESP32_PINMUX(18, ESP_NOSIG, ESP_FSPICS0_OUT)>;
				output-enable;
			};

			spim2_csel_gpio19: spim2_csel_gpio19 {
				pinmux = <ESP32_PINMUX(19, ESP_NOSIG, ESP_FSPICS0_OUT)>;
				output-enable;
			};

			spim2_csel_gpio20: spim2_csel_gpio20 {
				pinmux = <ESP32_PINMUX(20, ESP_NOSIG, ESP_FSPICS0_OUT)>;
				output-enable;
			};

			spim2_csel_gpio21: spim2_csel_gpio21 {
				pinmux = <ESP32_PINMUX(21, ESP_NOSIG, ESP_FSPICS0_OUT)>;
				output-enable;
			};

			spim2_csel_gpio26: spim2_csel_gpio26 {
				pinmux = <ESP32_PINMUX(26, ESP_NOSIG, ESP_FSPICS0_OUT)>;
				output-enable;
			};

			spim2_csel_gpio27: spim2_csel_gpio27 {
				pinmux = <ESP32_PINMUX(27, ESP_NOSIG, ESP_FSPICS0_OUT)>;
				output-enable;
			};

			spim2_csel_gpio28: spim2_csel_gpio28 {
				pinmux = <ESP32_PINMUX(28, ESP_NOSIG, ESP_FSPICS0_OUT)>;
				output-enable;
			};

			spim2_csel_gpio29: spim2_csel_gpio29 {
				pinmux = <ESP32_PINMUX(29, ESP_NOSIG, ESP_FSPICS0_OUT)>;
				output-enable;
			};

			spim2_csel_gpio30: spim2_csel_gpio30 {
				pinmux = <ESP32_PINMUX(30, ESP_NOSIG, ESP_FSPICS0_OUT)>;
				output-enable;
			};

			spim2_csel_gpio31: spim2_csel_gpio31 {
				pinmux = <ESP32_PINMUX(31, ESP_NOSIG, ESP_FSPICS0_OUT)>;
				output-enable;
			};

			spim2_csel_gpio32: spim2_csel_gpio32 {
				pinmux = <ESP32_PINMUX(32, ESP_NOSIG, ESP_FSPICS0_OUT)>;
				output-enable;
			};

			spim2_csel_gpio33: spim2_csel_gpio33 {
				pinmux = <ESP32_PINMUX(33, ESP_NOSIG, ESP_FSPICS0_OUT)>;
				output-enable;
			};

			spim2_csel_gpio34: spim2_csel_gpio34 {
				pinmux = <ESP32_PINMUX(34, ESP_NOSIG, ESP_FSPICS0_OUT)>;
				output-enable;
			};

			spim2_csel_gpio35: spim2_csel_gpio35 {
				pinmux = <ESP32_PINMUX(35, ESP_NOSIG, ESP_FSPICS0_OUT)>;
				output-enable;
			};

			spim2_csel_gpio36: spim2_csel_gpio36 {
				pinmux = <ESP32_PINMUX(36, ESP_NOSIG, ESP_FSPICS0_OUT)>;
				output-enable;
			};

			spim2_csel_gpio37: spim2_csel_gpio37 {
				pinmux = <ESP32_PINMUX(37, ESP_NOSIG, ESP_FSPICS0_OUT)>;
				output-enable;
			};

			spim2_csel_gpio38: spim2_csel_gpio38 {
				pinmux = <ESP32_PINMUX(38, ESP_NOSIG, ESP_FSPICS0_OUT)>;
				output-enable;
			};

			spim2_csel_gpio39: spim2_csel_gpio39 {
				pinmux = <ESP32_PINMUX(39, ESP_NOSIG, ESP_FSPICS0_OUT)>;
				output-enable;
			};

			spim2_csel_gpio40: spim2_csel_gpio40 {
				pinmux = <ESP32_PINMUX(40, ESP_NOSIG, ESP_FSPICS0_OUT)>;
				output-enable;
			};

			spim2_csel_gpio41: spim2_csel_gpio41 {
				pinmux = <ESP32_PINMUX(41, ESP_NOSIG, ESP_FSPICS0_OUT)>;
				output-enable;
			};

			spim2_csel_gpio42: spim2_csel_gpio42 {
				pinmux = <ESP32_PINMUX(42, ESP_NOSIG, ESP_FSPICS0_OUT)>;
				output-enable;
			};

			spim2_csel_gpio43: spim2_csel_gpio43 {
				pinmux = <ESP32_PINMUX(43, ESP_NOSIG, ESP_FSPICS0_OUT)>;
				output-enable;
			};

			spim2_csel_gpio44: spim2_csel_gpio44 {
				pinmux = <ESP32_PINMUX(44, ESP_NOSIG, ESP_FSPICS0_OUT)>;
				output-enable;
			};

			spim2_csel_gpio45: spim2_csel_gpio45 {
				pinmux = <ESP32_PINMUX(45, ESP_NOSIG, ESP_FSPICS0_OUT)>;
				output-enable;
			};

			/* SPIM2's MISO pin states */
			spim2_miso_gpio0: spim2_miso_gpio0 {
				pinmux = <ESP32_PINMUX(0, ESP_FSPIQ_IN, ESP_NOSIG)>;
				input-enable;
			};

			spim2_miso_gpio1: spim2_miso_gpio1 {
				pinmux = <ESP32_PINMUX(1, ESP_FSPIQ_IN, ESP_NOSIG)>;
				input-enable;
			};

			spim2_miso_gpio2: spim2_miso_gpio2 {
				pinmux = <ESP32_PINMUX(2, ESP_FSPIQ_IN, ESP_NOSIG)>;
				input-enable;
			};

			spim2_miso_gpio3: spim2_miso_gpio3 {
				pinmux = <ESP32_PINMUX(3, ESP_FSPIQ_IN, ESP_NOSIG)>;
				input-enable;
			};

			spim2_miso_gpio4: spim2_miso_gpio4 {
				pinmux = <ESP32_PINMUX(4, ESP_FSPIQ_IN, ESP_NOSIG)>;
				input-enable;
			};

			spim2_miso_gpio5: spim2_miso_gpio5 {
				pinmux = <ESP32_PINMUX(5, ESP_FSPIQ_IN, ESP_NOSIG)>;
				input-enable;
			};

			spim2_miso_gpio6: spim2_miso_gpio6 {
				pinmux = <ESP32_PINMUX(6, ESP_FSPIQ_IN, ESP_NOSIG)>;
				input-enable;
			};

			spim2_miso_gpio7: spim2_miso_gpio7 {
				pinmux = <ESP32_PINMUX(7, ESP_FSPIQ_IN, ESP_NOSIG)>;
				input-enable;
			};

			spim2_miso_gpio8: spim2_miso_gpio8 {
				pinmux = <ESP32_PINMUX(8, ESP_FSPIQ_IN, ESP_NOSIG)>;
				input-enable;
			};

			spim2_miso_gpio9: spim2_miso_gpio9 {
				pinmux = <ESP32_PINMUX(9, ESP_FSPIQ_IN, ESP_NOSIG)>;
				input-enable;
			};

			spim2_miso_gpio10: spim2_miso_gpio10 {
				pinmux = <ESP32_PINMUX(10, ESP_FSPIQ_IN, ESP_NOSIG)>;
				input-enable;
			};

			spim2_miso_gpio11: spim2_miso_gpio11 {
				pinmux = <ESP32_PINMUX(11, ESP_FSPIQ_IN, ESP_NOSIG)>;
				input-enable;
			};

			spim2_miso_gpio12: spim2_miso_gpio12 {
				pinmux = <ESP32_PINMUX(12, ESP_FSPIQ_IN, ESP_NOSIG)>;
				input-enable;
			};

			spim2_miso_gpio13: spim2_miso_gpio13 {
				pinmux = <ESP32_PINMUX(13, ESP_FSPIQ_IN, ESP_NOSIG)>;
				input-enable;
			};

			spim2_miso_gpio14: spim2_miso_gpio14 {
				pinmux = <ESP32_PINMUX(14, ESP_FSPIQ_IN, ESP_NOSIG)>;
				input-enable;
			};

			spim2_miso_gpio15: spim2_miso_gpio15 {
				pinmux = <ESP32_PINMUX(15, ESP_FSPIQ_IN, ESP_NOSIG)>;
				input-enable;
			};

			spim2_miso_gpio16: spim2_miso_gpio16 {
				pinmux = <ESP32_PINMUX(16, ESP_FSPIQ_IN, ESP_NOSIG)>;
				input-enable;
			};

			spim2_miso_gpio17: spim2_miso_gpio17 {
				pinmux = <ESP32_PINMUX(17, ESP_FSPIQ_IN, ESP_NOSIG)>;
				input-enable;
			};

			spim2_miso_gpio18: spim2_miso_gpio18 {
				pinmux = <ESP32_PINMUX(18, ESP_FSPIQ_IN, ESP_NOSIG)>;
				input-enable;
			};

			spim2_miso_gpio19: spim2_miso_gpio19 {
				pinmux = <ESP32_PINMUX(19, ESP_FSPIQ_IN, ESP_NOSIG)>;
				input-enable;
			};

			spim2_miso_gpio20: spim2_miso_gpio20 {
				pinmux = <ESP32_PINMUX(20, ESP_FSPIQ_IN, ESP_NOSIG)>;
				input-enable;
			};

			spim2_miso_gpio21: spim2_miso_gpio21 {
				pinmux = <ESP32_PINMUX(21, ESP_FSPIQ_IN, ESP_NOSIG)>;
				input-enable;
			};

			spim2_miso_gpio26: spim2_miso_gpio26 {
				pinmux = <ESP32_PINMUX(26, ESP_FSPIQ_IN, ESP_NOSIG)>;
				input-enable;
			};

			spim2_miso_gpio27: spim2_miso_gpio27 {
				pinmux = <ESP32_PINMUX(27, ESP_FSPIQ_IN, ESP_NOSIG)>;
				input-enable;
			};

			spim2_miso_gpio28: spim2_miso_gpio28 {
				pinmux = <ESP32_PINMUX(28, ESP_FSPIQ_IN, ESP_NOSIG)>;
				input-enable;
			};

			spim2_miso_gpio29: spim2_miso_gpio29 {
				pinmux = <ESP32_PINMUX(29, ESP_FSPIQ_IN, ESP_NOSIG)>;
				input-enable;
			};

			spim2_miso_gpio30: spim2_miso_gpio30 {
				pinmux = <ESP32_PINMUX(30, ESP_FSPIQ_IN, ESP_NOSIG)>;
				input-enable;
			};

			spim2_miso_gpio31: spim2_miso_gpio31 {
				pinmux = <ESP32_PINMUX(31, ESP_FSPIQ_IN, ESP_NOSIG)>;
				input-enable;
			};

			spim2_miso_gpio32: spim2_miso_gpio32 {
				pinmux = <ESP32_PINMUX(32, ESP_FSPIQ_IN, ESP_NOSIG)>;
				input-enable;
			};

			spim2_miso_gpio33: spim2_miso_gpio33 {
				pinmux = <ESP32_PINMUX(33, ESP_FSPIQ_IN, ESP_NOSIG)>;
				input-enable;
			};

			spim2_miso_gpio34: spim2_miso_gpio34 {
				pinmux = <ESP32_PINMUX(34, ESP_FSPIQ_IN, ESP_NOSIG)>;
				input-enable;
			};

			spim2_miso_gpio35: spim2_miso_gpio35 {
				pinmux = <ESP32_PINMUX(35, ESP_FSPIQ_IN, ESP_NOSIG)>;
				input-enable;
			};

			spim2_miso_gpio36: spim2_miso_gpio36 {
				pinmux = <ESP32_PINMUX(36, ESP_FSPIQ_IN, ESP_NOSIG)>;
				input-enable;
			};

			spim2_miso_gpio37: spim2_miso_gpio37 {
				pinmux = <ESP32_PINMUX(37, ESP_FSPIQ_IN, ESP_NOSIG)>;
				input-enable;
			};

			spim2_miso_gpio38: spim2_miso_gpio38 {
				pinmux = <ESP32_PINMUX(38, ESP_FSPIQ_IN, ESP_NOSIG)>;
				input-enable;
			};

			spim2_miso_gpio39: spim2_miso_gpio39 {
				pinmux = <ESP32_PINMUX(39, ESP_FSPIQ_IN, ESP_NOSIG)>;
				input-enable;
			};

			spim2_miso_gpio40: spim2_miso_gpio40 {
				pinmux = <ESP32_PINMUX(40, ESP_FSPIQ_IN, ESP_NOSIG)>;
				input-enable;
			};

			spim2_miso_gpio41: spim2_miso_gpio41 {
				pinmux = <ESP32_PINMUX(41, ESP_FSPIQ_IN, ESP_NOSIG)>;
				input-enable;
			};

			spim2_miso_gpio42: spim2_miso_gpio42 {
				pinmux = <ESP32_PINMUX(42, ESP_FSPIQ_IN, ESP_NOSIG)>;
				input-enable;
			};

			spim2_miso_gpio43: spim2_miso_gpio43 {
				pinmux = <ESP32_PINMUX(43, ESP_FSPIQ_IN, ESP_NOSIG)>;
				input-enable;
			};

			spim2_miso_gpio44: spim2_miso_gpio44 {
				pinmux = <ESP32_PINMUX(44, ESP_FSPIQ_IN, ESP_NOSIG)>;
				input-enable;
			};

			spim2_miso_gpio45: spim2_miso_gpio45 {
				pinmux = <ESP32_PINMUX(45, ESP_FSPIQ_IN, ESP_NOSIG)>;
				input-enable;
			};

			spim2_miso_gpio46: spim2_miso_gpio46 {
				pinmux = <ESP32_PINMUX(46, ESP_FSPIQ_IN, ESP_NOSIG)>;
				input-enable;
			};

			/* SPIM2's MOSI pin states */
			spim2_mosi_gpio0: spim2_mosi_gpio0 {
				pinmux = <ESP32_PINMUX(0, ESP_NOSIG, ESP_FSPID_OUT)>;
				output-low;
			};

			spim2_mosi_gpio1: spim2_mosi_gpio1 {
				pinmux = <ESP32_PINMUX(1, ESP_NOSIG, ESP_FSPID_OUT)>;
				output-low;
			};

			spim2_mosi_gpio2: spim2_mosi_gpio2 {
				pinmux = <ESP32_PINMUX(2, ESP_NOSIG, ESP_FSPID_OUT)>;
				output-low;
			};

			spim2_mosi_gpio3: spim2_mosi_gpio3 {
				pinmux = <ESP32_PINMUX(3, ESP_NOSIG, ESP_FSPID_OUT)>;
				output-low;
			};

			spim2_mosi_gpio4: spim2_mosi_gpio4 {
				pinmux = <ESP32_PINMUX(4, ESP_NOSIG, ESP_FSPID_OUT)>;
				output-low;
			};

			spim2_mosi_gpio5: spim2_mosi_gpio5 {
				pinmux = <ESP32_PINMUX(5, ESP_NOSIG, ESP_FSPID_OUT)>;
				output-low;
			};

			spim2_mosi_gpio6: spim2_mosi_gpio6 {
				pinmux = <ESP32_PINMUX(6, ESP_NOSIG, ESP_FSPID_OUT)>;
				output-low;
			};

			spim2_mosi_gpio7: spim2_mosi_gpio7 {
				pinmux = <ESP32_PINMUX(7, ESP_NOSIG, ESP_FSPID_OUT)>;
				output-low;
			};

			spim2_mosi_gpio8: spim2_mosi_gpio8 {
				pinmux = <ESP32_PINMUX(8, ESP_NOSIG, ESP_FSPID_OUT)>;
				output-low;
			};

			spim2_mosi_gpio9: spim2_mosi_gpio9 {
				pinmux = <ESP32_PINMUX(9, ESP_NOSIG, ESP_FSPID_OUT)>;
				output-low;
			};

			spim2_mosi_gpio10: spim2_mosi_gpio10 {
				pinmux = <ESP32_PINMUX(10, ESP_NOSIG, ESP_FSPID_OUT)>;
				output-low;
			};

			spim2_mosi_gpio11: spim2_mosi_gpio11 {
				pinmux = <ESP32_PINMUX(11, ESP_NOSIG, ESP_FSPID_OUT)>;
				output-low;
			};

			spim2_mosi_gpio12: spim2_mosi_gpio12 {
				pinmux = <ESP32_PINMUX(12, ESP_NOSIG, ESP_FSPID_OUT)>;
				output-low;
			};

			spim2_mosi_gpio13: spim2_mosi_gpio13 {
				pinmux = <ESP32_PINMUX(13, ESP_NOSIG, ESP_FSPID_OUT)>;
				output-low;
			};

			spim2_mosi_gpio14: spim2_mosi_gpio14 {
				pinmux = <ESP32_PINMUX(14, ESP_NOSIG, ESP_FSPID_OUT)>;
				output-low;
			};

			spim2_mosi_gpio15: spim2_mosi_gpio15 {
				pinmux = <ESP32_PINMUX(15, ESP_NOSIG, ESP_FSPID_OUT)>;
				output-low;
			};

			spim2_mosi_gpio16: spim2_mosi_gpio16 {
				pinmux = <ESP32_PINMUX(16, ESP_NOSIG, ESP_FSPID_OUT)>;
				output-low;
			};

			spim2_mosi_gpio17: spim2_mosi_gpio17 {
				pinmux = <ESP32_PINMUX(17, ESP_NOSIG, ESP_FSPID_OUT)>;
				output-low;
			};

			spim2_mosi_gpio18: spim2_mosi_gpio18 {
				pinmux = <ESP32_PINMUX(18, ESP_NOSIG, ESP_FSPID_OUT)>;
				output-low;
			};

			spim2_mosi_gpio19: spim2_mosi_gpio19 {
				pinmux = <ESP32_PINMUX(19, ESP_NOSIG, ESP_FSPID_OUT)>;
				output-low;
			};

			spim2_mosi_gpio20: spim2_mosi_gpio20 {
				pinmux = <ESP32_PINMUX(20, ESP_NOSIG, ESP_FSPID_OUT)>;
				output-low;
			};

			spim2_mosi_gpio21: spim2_mosi_gpio21 {
				pinmux = <ESP32_PINMUX(21, ESP_NOSIG, ESP_FSPID_OUT)>;
				output-low;
			};

			spim2_mosi_gpio26: spim2_mosi_gpio26 {
				pinmux = <ESP32_PINMUX(26, ESP_NOSIG, ESP_FSPID_OUT)>;
				output-low;
			};

			spim2_mosi_gpio27: spim2_mosi_gpio27 {
				pinmux = <ESP32_PINMUX(27, ESP_NOSIG, ESP_FSPID_OUT)>;
				output-low;
			};

			spim2_mosi_gpio28: spim2_mosi_gpio28 {
				pinmux = <ESP32_PINMUX(28, ESP_NOSIG, ESP_FSPID_OUT)>;
				output-low;
			};

			spim2_mosi_gpio29: spim2_mosi_gpio29 {
				pinmux = <ESP32_PINMUX(29, ESP_NOSIG, ESP_FSPID_OUT)>;
				output-low;
			};

			spim2_mosi_gpio30: spim2_mosi_gpio30 {
				pinmux = <ESP32_PINMUX(30, ESP_NOSIG, ESP_FSPID_OUT)>;
				output-low;
			};

			spim2_mosi_gpio31: spim2_mosi_gpio31 {
				pinmux = <ESP32_PINMUX(31, ESP_NOSIG, ESP_FSPID_OUT)>;
				output-low;
			};

			spim2_mosi_gpio32: spim2_mosi_gpio32 {
				pinmux = <ESP32_PINMUX(32, ESP_NOSIG, ESP_FSPID_OUT)>;
				output-low;
			};

			spim2_mosi_gpio33: spim2_mosi_gpio33 {
				pinmux = <ESP32_PINMUX(33, ESP_NOSIG, ESP_FSPID_OUT)>;
				output-low;
			};

			spim2_mosi_gpio34: spim2_mosi_gpio34 {
				pinmux = <ESP32_PINMUX(34, ESP_NOSIG, ESP_FSPID_OUT)>;
				output-low;
			};

			spim2_mosi_gpio35: spim2_mosi_gpio35 {
				pinmux = <ESP32_PINMUX(35, ESP_NOSIG, ESP_FSPID_OUT)>;
				output-low;
			};

			spim2_mosi_gpio36: spim2_mosi_gpio36 {
				pinmux = <ESP32_PINMUX(36, ESP_NOSIG, ESP_FSPID_OUT)>;
				output-low;
			};

			spim2_mosi_gpio37: spim2_mosi_gpio37 {
				pinmux = <ESP32_PINMUX(37, ESP_NOSIG, ESP_FSPID_OUT)>;
				output-low;
			};

			spim2_mosi_gpio38: spim2_mosi_gpio38 {
				pinmux = <ESP32_PINMUX(38, ESP_NOSIG, ESP_FSPID_OUT)>;
				output-low;
			};

			spim2_mosi_gpio39: spim2_mosi_gpio39 {
				pinmux = <ESP32_PINMUX(39, ESP_NOSIG, ESP_FSPID_OUT)>;
				output-low;
			};

			spim2_mosi_gpio40: spim2_mosi_gpio40 {
				pinmux = <ESP32_PINMUX(40, ESP_NOSIG, ESP_FSPID_OUT)>;
				output-low;
			};

			spim2_mosi_gpio41: spim2_mosi_gpio41 {
				pinmux = <ESP32_PINMUX(41, ESP_NOSIG, ESP_FSPID_OUT)>;
				output-low;
			};

			spim2_mosi_gpio42: spim2_mosi_gpio42 {
				pinmux = <ESP32_PINMUX(42, ESP_NOSIG, ESP_FSPID_OUT)>;
				output-low;
			};

			spim2_mosi_gpio43: spim2_mosi_gpio43 {
				pinmux = <ESP32_PINMUX(43, ESP_NOSIG, ESP_FSPID_OUT)>;
				output-low;
			};

			spim2_mosi_gpio44: spim2_mosi_gpio44 {
				pinmux = <ESP32_PINMUX(44, ESP_NOSIG, ESP_FSPID_OUT)>;
				output-low;
			};

			spim2_mosi_gpio45: spim2_mosi_gpio45 {
				pinmux = <ESP32_PINMUX(45, ESP_NOSIG, ESP_FSPID_OUT)>;
				output-low;
			};

			/* SPIM2's SCLK pin states */
			spim2_sclk_gpio0: spim2_sclk_gpio0 {
				pinmux = <ESP32_PINMUX(0, ESP_NOSIG, ESP_FSPICLK_OUT)>;
				output-enable;
			};

			spim2_sclk_gpio1: spim2_sclk_gpio1 {
				pinmux = <ESP32_PINMUX(1, ESP_NOSIG, ESP_FSPICLK_OUT)>;
				output-enable;
			};

			spim2_sclk_gpio2: spim2_sclk_gpio2 {
				pinmux = <ESP32_PINMUX(2, ESP_NOSIG, ESP_FSPICLK_OUT)>;
				output-enable;
			};

			spim2_sclk_gpio3: spim2_sclk_gpio3 {
				pinmux = <ESP32_PINMUX(3, ESP_NOSIG, ESP_FSPICLK_OUT)>;
				output-enable;
			};

			spim2_sclk_gpio4: spim2_sclk_gpio4 {
				pinmux = <ESP32_PINMUX(4, ESP_NOSIG, ESP_FSPICLK_OUT)>;
				output-enable;
			};

			spim2_sclk_gpio5: spim2_sclk_gpio5 {
				pinmux = <ESP32_PINMUX(5, ESP_NOSIG, ESP_FSPICLK_OUT)>;
				output-enable;
			};

			spim2_sclk_gpio6: spim2_sclk_gpio6 {
				pinmux = <ESP32_PINMUX(6, ESP_NOSIG, ESP_FSPICLK_OUT)>;
				output-enable;
			};

			spim2_sclk_gpio7: spim2_sclk_gpio7 {
				pinmux = <ESP32_PINMUX(7, ESP_NOSIG, ESP_FSPICLK_OUT)>;
				output-enable;
			};

			spim2_sclk_gpio8: spim2_sclk_gpio8 {
				pinmux = <ESP32_PINMUX(8, ESP_NOSIG, ESP_FSPICLK_OUT)>;
				output-enable;
			};

			spim2_sclk_gpio9: spim2_sclk_gpio9 {
				pinmux = <ESP32_PINMUX(9, ESP_NOSIG, ESP_FSPICLK_OUT)>;
				output-enable;
			};

			spim2_sclk_gpio10: spim2_sclk_gpio10 {
				pinmux = <ESP32_PINMUX(10, ESP_NOSIG, ESP_FSPICLK_OUT)>;
				output-enable;
			};

			spim2_sclk_gpio11: spim2_sclk_gpio11 {
				pinmux = <ESP32_PINMUX(11, ESP_NOSIG, ESP_FSPICLK_OUT)>;
				output-enable;
			};

			spim2_sclk_gpio12: spim2_sclk_gpio12 {
				pinmux = <ESP32_PINMUX(12, ESP_NOSIG, ESP_FSPICLK_OUT)>;
				output-enable;
			};

			spim2_sclk_gpio13: spim2_sclk_gpio13 {
				pinmux = <ESP32_PINMUX(13, ESP_NOSIG, ESP_FSPICLK_OUT)>;
				output-enable;
			};

			spim2_sclk_gpio14: spim2_sclk_gpio14 {
				pinmux = <ESP32_PINMUX(14, ESP_NOSIG, ESP_FSPICLK_OUT)>;
				output-enable;
			};

			spim2_sclk_gpio15: spim2_sclk_gpio15 {
				pinmux = <ESP32_PINMUX(15, ESP_NOSIG, ESP_FSPICLK_OUT)>;
				output-enable;
			};

			spim2_sclk_gpio16: spim2_sclk_gpio16 {
				pinmux = <ESP32_PINMUX(16, ESP_NOSIG, ESP_FSPICLK_OUT)>;
				output-enable;
			};

			spim2_sclk_gpio17: spim2_sclk_gpio17 {
				pinmux = <ESP32_PINMUX(17, ESP_NOSIG, ESP_FSPICLK_OUT)>;
				output-enable;
			};

			spim2_sclk_gpio18: spim2_sclk_gpio18 {
				pinmux = <ESP32_PINMUX(18, ESP_NOSIG, ESP_FSPICLK_OUT)>;
				output-enable;
			};

			spim2_sclk_gpio19: spim2_sclk_gpio19 {
				pinmux = <ESP32_PINMUX(19, ESP_NOSIG, ESP_FSPICLK_OUT)>;
				output-enable;
			};

			spim2_sclk_gpio20: spim2_sclk_gpio20 {
				pinmux = <ESP32_PINMUX(20, ESP_NOSIG, ESP_FSPICLK_OUT)>;
				output-enable;
			};

			spim2_sclk_gpio21: spim2_sclk_gpio21 {
				pinmux = <ESP32_PINMUX(21, ESP_NOSIG, ESP_FSPICLK_OUT)>;
				output-enable;
			};

			spim2_sclk_gpio26: spim2_sclk_gpio26 {
				pinmux = <ESP32_PINMUX(26, ESP_NOSIG, ESP_FSPICLK_OUT)>;
				output-enable;
			};

			spim2_sclk_gpio27: spim2_sclk_gpio27 {
				pinmux = <ESP32_PINMUX(27, ESP_NOSIG, ESP_FSPICLK_OUT)>;
				output-enable;
			};

			spim2_sclk_gpio28: spim2_sclk_gpio28 {
				pinmux = <ESP32_PINMUX(28, ESP_NOSIG, ESP_FSPICLK_OUT)>;
				output-enable;
			};

			spim2_sclk_gpio29: spim2_sclk_gpio29 {
				pinmux = <ESP32_PINMUX(29, ESP_NOSIG, ESP_FSPICLK_OUT)>;
				output-enable;
			};

			spim2_sclk_gpio30: spim2_sclk_gpio30 {
				pinmux = <ESP32_PINMUX(30, ESP_NOSIG, ESP_FSPICLK_OUT)>;
				output-enable;
			};

			spim2_sclk_gpio31: spim2_sclk_gpio31 {
				pinmux = <ESP32_PINMUX(31, ESP_NOSIG, ESP_FSPICLK_OUT)>;
				output-enable;
			};

			spim2_sclk_gpio32: spim2_sclk_gpio32 {
				pinmux = <ESP32_PINMUX(32, ESP_NOSIG, ESP_FSPICLK_OUT)>;
				output-enable;
			};

			spim2_sclk_gpio33: spim2_sclk_gpio33 {
				pinmux = <ESP32_PINMUX(33, ESP_NOSIG, ESP_FSPICLK_OUT)>;
				output-enable;
			};

			spim2_sclk_gpio34: spim2_sclk_gpio34 {
				pinmux = <ESP32_PINMUX(34, ESP_NOSIG, ESP_FSPICLK_OUT)>;
				output-enable;
			};

			spim2_sclk_gpio35: spim2_sclk_gpio35 {
				pinmux = <ESP32_PINMUX(35, ESP_NOSIG, ESP_FSPICLK_OUT)>;
				output-enable;
			};

			spim2_sclk_gpio36: spim2_sclk_gpio36 {
				pinmux = <ESP32_PINMUX(36, ESP_NOSIG, ESP_FSPICLK_OUT)>;
				output-enable;
			};

			spim2_sclk_gpio37: spim2_sclk_gpio37 {
				pinmux = <ESP32_PINMUX(37, ESP_NOSIG, ESP_FSPICLK_OUT)>;
				output-enable;
			};

			spim2_sclk_gpio38: spim2_sclk_gpio38 {
				pinmux = <ESP32_PINMUX(38, ESP_NOSIG, ESP_FSPICLK_OUT)>;
				output-enable;
			};

			spim2_sclk_gpio39: spim2_sclk_gpio39 {
				pinmux = <ESP32_PINMUX(39, ESP_NOSIG, ESP_FSPICLK_OUT)>;
				output-enable;
			};

			spim2_sclk_gpio40: spim2_sclk_gpio40 {
				pinmux = <ESP32_PINMUX(40, ESP_NOSIG, ESP_FSPICLK_OUT)>;
				output-enable;
			};

			spim2_sclk_gpio41: spim2_sclk_gpio41 {
				pinmux = <ESP32_PINMUX(41, ESP_NOSIG, ESP_FSPICLK_OUT)>;
				output-enable;
			};

			spim2_sclk_gpio42: spim2_sclk_gpio42 {
				pinmux = <ESP32_PINMUX(42, ESP_NOSIG, ESP_FSPICLK_OUT)>;
				output-enable;
			};

			spim2_sclk_gpio43: spim2_sclk_gpio43 {
				pinmux = <ESP32_PINMUX(43, ESP_NOSIG, ESP_FSPICLK_OUT)>;
				output-enable;
			};

			spim2_sclk_gpio44: spim2_sclk_gpio44 {
				pinmux = <ESP32_PINMUX(44, ESP_NOSIG, ESP_FSPICLK_OUT)>;
				output-enable;
			};

			spim2_sclk_gpio45: spim2_sclk_gpio45 {
				pinmux = <ESP32_PINMUX(45, ESP_NOSIG, ESP_FSPICLK_OUT)>;
				output-enable;
			};

			/* SPIM3's CSEL pin states */
			spim3_csel_gpio0: spim3_csel_gpio0 {
				pinmux = <ESP32_PINMUX(0, ESP_NOSIG, ESP_SPI3_CS0_OUT)>;
				output-enable;
			};

			spim3_csel_gpio1: spim3_csel_gpio1 {
				pinmux = <ESP32_PINMUX(1, ESP_NOSIG, ESP_SPI3_CS0_OUT)>;
				output-enable;
			};

			spim3_csel_gpio2: spim3_csel_gpio2 {
				pinmux = <ESP32_PINMUX(2, ESP_NOSIG, ESP_SPI3_CS0_OUT)>;
				output-enable;
			};

			spim3_csel_gpio3: spim3_csel_gpio3 {
				pinmux = <ESP32_PINMUX(3, ESP_NOSIG, ESP_SPI3_CS0_OUT)>;
				output-enable;
			};

			spim3_csel_gpio4: spim3_csel_gpio4 {
				pinmux = <ESP32_PINMUX(4, ESP_NOSIG, ESP_SPI3_CS0_OUT)>;
				output-enable;
			};

			spim3_csel_gpio5: spim3_csel_gpio5 {
				pinmux = <ESP32_PINMUX(5, ESP_NOSIG, ESP_SPI3_CS0_OUT)>;
				output-enable;
			};

			spim3_csel_gpio6: spim3_csel_gpio6 {
				pinmux = <ESP32_PINMUX(6, ESP_NOSIG, ESP_SPI3_CS0_OUT)>;
				output-enable;
			};

			spim3_csel_gpio7: spim3_csel_gpio7 {
				pinmux = <ESP32_PINMUX(7, ESP_NOSIG, ESP_SPI3_CS0_OUT)>;
				output-enable;
			};

			spim3_csel_gpio8: spim3_csel_gpio8 {
				pinmux = <ESP32_PINMUX(8, ESP_NOSIG, ESP_SPI3_CS0_OUT)>;
				output-enable;
			};

			spim3_csel_gpio9: spim3_csel_gpio9 {
				pinmux = <ESP32_PINMUX(9, ESP_NOSIG, ESP_SPI3_CS0_OUT)>;
				output-enable;
			};

			spim3_csel_gpio10: spim3_csel_gpio10 {
				pinmux = <ESP32_PINMUX(10, ESP_NOSIG, ESP_SPI3_CS0_OUT)>;
				output-enable;
			};

			spim3_csel_gpio11: spim3_csel_gpio11 {
				pinmux = <ESP32_PINMUX(11, ESP_NOSIG, ESP_SPI3_CS0_OUT)>;
				output-enable;
			};

			spim3_csel_gpio12: spim3_csel_gpio12 {
				pinmux = <ESP32_PINMUX(12, ESP_NOSIG, ESP_SPI3_CS0_OUT)>;
				output-enable;
			};

			spim3_csel_gpio13: spim3_csel_gpio13 {
				pinmux = <ESP32_PINMUX(13, ESP_NOSIG, ESP_SPI3_CS0_OUT)>;
				output-enable;
			};

			spim3_csel_gpio14: spim3_csel_gpio14 {
				pinmux = <ESP32_PINMUX(14, ESP_NOSIG, ESP_SPI3_CS0_OUT)>;
				output-enable;
			};

			spim3_csel_gpio15: spim3_csel_gpio15 {
				pinmux = <ESP32_PINMUX(15, ESP_NOSIG, ESP_SPI3_CS0_OUT)>;
				output-enable;
			};

			spim3_csel_gpio16: spim3_csel_gpio16 {
				pinmux = <ESP32_PINMUX(16, ESP_NOSIG, ESP_SPI3_CS0_OUT)>;
				output-enable;
			};

			spim3_csel_gpio17: spim3_csel_gpio17 {
				pinmux = <ESP32_PINMUX(17, ESP_NOSIG, ESP_SPI3_CS0_OUT)>;
				output-enable;
			};

			spim3_csel_gpio18: spim3_csel_gpio18 {
				pinmux = <ESP32_PINMUX(18, ESP_NOSIG, ESP_SPI3_CS0_OUT)>;
				output-enable;
			};

			spim3_csel_gpio19: spim3_csel_gpio19 {
				pinmux = <ESP32_PINMUX(19, ESP_NOSIG, ESP_SPI3_CS0_OUT)>;
				output-enable;
			};

			spim3_csel_gpio20: spim3_csel_gpio20 {
				pinmux = <ESP32_PINMUX(20, ESP_NOSIG, ESP_SPI3_CS0_OUT)>;
				output-enable;
			};

			spim3_csel_gpio21: spim3_csel_gpio21 {
				pinmux = <ESP32_PINMUX(21, ESP_NOSIG, ESP_SPI3_CS0_OUT)>;
				output-enable;
			};

			spim3_csel_gpio26: spim3_csel_gpio26 {
				pinmux = <ESP32_PINMUX(26, ESP_NOSIG, ESP_SPI3_CS0_OUT)>;
				output-enable;
			};

			spim3_csel_gpio27: spim3_csel_gpio27 {
				pinmux = <ESP32_PINMUX(27, ESP_NOSIG, ESP_SPI3_CS0_OUT)>;
				output-enable;
			};

			spim3_csel_gpio28: spim3_csel_gpio28 {
				pinmux = <ESP32_PINMUX(28, ESP_NOSIG, ESP_SPI3_CS0_OUT)>;
				output-enable;
			};

			spim3_csel_gpio29: spim3_csel_gpio29 {
				pinmux = <ESP32_PINMUX(29, ESP_NOSIG, ESP_SPI3_CS0_OUT)>;
				output-enable;
			};

			spim3_csel_gpio30: spim3_csel_gpio30 {
				pinmux = <ESP32_PINMUX(30, ESP_NOSIG, ESP_SPI3_CS0_OUT)>;
				output-enable;
			};

			spim3_csel_gpio31: spim3_csel_gpio31 {
				pinmux = <ESP32_PINMUX(31, ESP_NOSIG, ESP_SPI3_CS0_OUT)>;
				output-enable;
			};

			spim3_csel_gpio32: spim3_csel_gpio32 {
				pinmux = <ESP32_PINMUX(32, ESP_NOSIG, ESP_SPI3_CS0_OUT)>;
				output-enable;
			};

			spim3_csel_gpio33: spim3_csel_gpio33 {
				pinmux = <ESP32_PINMUX(33, ESP_NOSIG, ESP_SPI3_CS0_OUT)>;
				output-enable;
			};

			spim3_csel_gpio34: spim3_csel_gpio34 {
				pinmux = <ESP32_PINMUX(34, ESP_NOSIG, ESP_SPI3_CS0_OUT)>;
				output-enable;
			};

			spim3_csel_gpio35: spim3_csel_gpio35 {
				pinmux = <ESP32_PINMUX(35, ESP_NOSIG, ESP_SPI3_CS0_OUT)>;
				output-enable;
			};

			spim3_csel_gpio36: spim3_csel_gpio36 {
				pinmux = <ESP32_PINMUX(36, ESP_NOSIG, ESP_SPI3_CS0_OUT)>;
				output-enable;
			};

			spim3_csel_gpio37: spim3_csel_gpio37 {
				pinmux = <ESP32_PINMUX(37, ESP_NOSIG, ESP_SPI3_CS0_OUT)>;
				output-enable;
			};

			spim3_csel_gpio38: spim3_csel_gpio38 {
				pinmux = <ESP32_PINMUX(38, ESP_NOSIG, ESP_SPI3_CS0_OUT)>;
				output-enable;
			};

			spim3_csel_gpio39: spim3_csel_gpio39 {
				pinmux = <ESP32_PINMUX(39, ESP_NOSIG, ESP_SPI3_CS0_OUT)>;
				output-enable;
			};

			spim3_csel_gpio40: spim3_csel_gpio40 {
				pinmux = <ESP32_PINMUX(40, ESP_NOSIG, ESP_SPI3_CS0_OUT)>;
				output-enable;
			};

			spim3_csel_gpio41: spim3_csel_gpio41 {
				pinmux = <ESP32_PINMUX(41, ESP_NOSIG, ESP_SPI3_CS0_OUT)>;
				output-enable;
			};

			spim3_csel_gpio42: spim3_csel_gpio42 {
				pinmux = <ESP32_PINMUX(42, ESP_NOSIG, ESP_SPI3_CS0_OUT)>;
				output-enable;
			};

			spim3_csel_gpio43: spim3_csel_gpio43 {
				pinmux = <ESP32_PINMUX(43, ESP_NOSIG, ESP_SPI3_CS0_OUT)>;
				output-enable;
			};

			spim3_csel_gpio44: spim3_csel_gpio44 {
				pinmux = <ESP32_PINMUX(44, ESP_NOSIG, ESP_SPI3_CS0_OUT)>;
				output-enable;
			};

			spim3_csel_gpio45: spim3_csel_gpio45 {
				pinmux = <ESP32_PINMUX(45, ESP_NOSIG, ESP_SPI3_CS0_OUT)>;
				output-enable;
			};

			/* SPIM3's MISO pin states */
			spim3_miso_gpio0: spim3_miso_gpio0 {
				pinmux = <ESP32_PINMUX(0, ESP_SPI3_Q_IN, ESP_NOSIG)>;
				input-enable;
			};

			spim3_miso_gpio1: spim3_miso_gpio1 {
				pinmux = <ESP32_PINMUX(1, ESP_SPI3_Q_IN, ESP_NOSIG)>;
				input-enable;
			};

			spim3_miso_gpio2: spim3_miso_gpio2 {
				pinmux = <ESP32_PINMUX(2, ESP_SPI3_Q_IN, ESP_NOSIG)>;
				input-enable;
			};

			spim3_miso_gpio3: spim3_miso_gpio3 {
				pinmux = <ESP32_PINMUX(3, ESP_SPI3_Q_IN, ESP_NOSIG)>;
				input-enable;
			};

			spim3_miso_gpio4: spim3_miso_gpio4 {
				pinmux = <ESP32_PINMUX(4, ESP_SPI3_Q_IN, ESP_NOSIG)>;
				input-enable;
			};

			spim3_miso_gpio5: spim3_miso_gpio5 {
				pinmux = <ESP32_PINMUX(5, ESP_SPI3_Q_IN, ESP_NOSIG)>;
				input-enable;
			};

			spim3_miso_gpio6: spim3_miso_gpio6 {
				pinmux = <ESP32_PINMUX(6, ESP_SPI3_Q_IN, ESP_NOSIG)>;
				input-enable;
			};

			spim3_miso_gpio7: spim3_miso_gpio7 {
				pinmux = <ESP32_PINMUX(7, ESP_SPI3_Q_IN, ESP_NOSIG)>;
				input-enable;
			};

			spim3_miso_gpio8: spim3_miso_gpio8 {
				pinmux = <ESP32_PINMUX(8, ESP_SPI3_Q_IN, ESP_NOSIG)>;
				input-enable;
			};

			spim3_miso_gpio9: spim3_miso_gpio9 {
				pinmux = <ESP32_PINMUX(9, ESP_SPI3_Q_IN, ESP_NOSIG)>;
				input-enable;
			};

			spim3_miso_gpio10: spim3_miso_gpio10 {
				pinmux = <ESP32_PINMUX(10, ESP_SPI3_Q_IN, ESP_NOSIG)>;
				input-enable;
			};

			spim3_miso_gpio11: spim3_miso_gpio11 {
				pinmux = <ESP32_PINMUX(11, ESP_SPI3_Q_IN, ESP_NOSIG)>;
				input-enable;
			};

			spim3_miso_gpio12: spim3_miso_gpio12 {
				pinmux = <ESP32_PINMUX(12, ESP_SPI3_Q_IN, ESP_NOSIG)>;
				input-enable;
			};

			spim3_miso_gpio13: spim3_miso_gpio13 {
				pinmux = <ESP32_PINMUX(13, ESP_SPI3_Q_IN, ESP_NOSIG)>;
				input-enable;
			};

			spim3_miso_gpio14: spim3_miso_gpio14 {
				pinmux = <ESP32_PINMUX(14, ESP_SPI3_Q_IN, ESP_NOSIG)>;
				input-enable;
			};

			spim3_miso_gpio15: spim3_miso_gpio15 {
				pinmux = <ESP32_PINMUX(15, ESP_SPI3_Q_IN, ESP_NOSIG)>;
				input-enable;
			};

			spim3_miso_gpio16: spim3_miso_gpio16 {
				pinmux = <ESP32_PINMUX(16, ESP_SPI3_Q_IN, ESP_NOSIG)>;
				input-enable;
			};

			spim3_miso_gpio17: spim3_miso_gpio17 {
				pinmux = <ESP32_PINMUX(17, ESP_SPI3_Q_IN, ESP_NOSIG)>;
				input-enable;
			};

			spim3_miso_gpio18: spim3_miso_gpio18 {
				pinmux = <ESP32_PINMUX(18, ESP_SPI3_Q_IN, ESP_NOSIG)>;
				input-enable;
			};

			spim3_miso_gpio19: spim3_miso_gpio19 {
				pinmux = <ESP32_PINMUX(19, ESP_SPI3_Q_IN, ESP_NOSIG)>;
				input-enable;
			};

			spim3_miso_gpio20: spim3_miso_gpio20 {
				pinmux = <ESP32_PINMUX(20, ESP_SPI3_Q_IN, ESP_NOSIG)>;
				input-enable;
			};

			spim3_miso_gpio21: spim3_miso_gpio21 {
				pinmux = <ESP32_PINMUX(21, ESP_SPI3_Q_IN, ESP_NOSIG)>;
				input-enable;
			};

			spim3_miso_gpio26: spim3_miso_gpio26 {
				pinmux = <ESP32_PINMUX(26, ESP_SPI3_Q_IN, ESP_NOSIG)>;
				input-enable;
			};

			spim3_miso_gpio27: spim3_miso_gpio27 {
				pinmux = <ESP32_PINMUX(27, ESP_SPI3_Q_IN, ESP_NOSIG)>;
				input-enable;
			};

			spim3_miso_gpio28: spim3_miso_gpio28 {
				pinmux = <ESP32_PINMUX(28, ESP_SPI3_Q_IN, ESP_NOSIG)>;
				input-enable;
			};

			spim3_miso_gpio29: spim3_miso_gpio29 {
				pinmux = <ESP32_PINMUX(29, ESP_SPI3_Q_IN, ESP_NOSIG)>;
				input-enable;
			};

			spim3_miso_gpio30: spim3_miso_gpio30 {
				pinmux = <ESP32_PINMUX(30, ESP_SPI3_Q_IN, ESP_NOSIG)>;
				input-enable;
			};

			spim3_miso_gpio31: spim3_miso_gpio31 {
				pinmux = <ESP32_PINMUX(31, ESP_SPI3_Q_IN, ESP_NOSIG)>;
				input-enable;
			};

			spim3_miso_gpio32: spim3_miso_gpio32 {
				pinmux = <ESP32_PINMUX(32, ESP_SPI3_Q_IN, ESP_NOSIG)>;
				input-enable;
			};

			spim3_miso_gpio33: spim3_miso_gpio33 {
				pinmux = <ESP32_PINMUX(33, ESP_SPI3_Q_IN, ESP_NOSIG)>;
				input-enable;
			};

			spim3_miso_gpio34: spim3_miso_gpio34 {
				pinmux = <ESP32_PINMUX(34, ESP_SPI3_Q_IN, ESP_NOSIG)>;
				input-enable;
			};

			spim3_miso_gpio35: spim3_miso_gpio35 {
				pinmux = <ESP32_PINMUX(35, ESP_SPI3_Q_IN, ESP_NOSIG)>;
				input-enable;
			};

			spim3_miso_gpio36: spim3_miso_gpio36 {
				pinmux = <ESP32_PINMUX(36, ESP_SPI3_Q_IN, ESP_NOSIG)>;
				input-enable;
			};

			spim3_miso_gpio37: spim3_miso_gpio37 {
				pinmux = <ESP32_PINMUX(37, ESP_SPI3_Q_IN, ESP_NOSIG)>;
				input-enable;
			};

			spim3_miso_gpio38: spim3_miso_gpio38 {
				pinmux = <ESP32_PINMUX(38, ESP_SPI3_Q_IN, ESP_NOSIG)>;
				input-enable;
			};

			spim3_miso_gpio39: spim3_miso_gpio39 {
				pinmux = <ESP32_PINMUX(39, ESP_SPI3_Q_IN, ESP_NOSIG)>;
				input-enable;
			};

			spim3_miso_gpio40: spim3_miso_gpio40 {
				pinmux = <ESP32_PINMUX(40, ESP_SPI3_Q_IN, ESP_NOSIG)>;
				input-enable;
			};

			spim3_miso_gpio41: spim3_miso_gpio41 {
				pinmux = <ESP32_PINMUX(41, ESP_SPI3_Q_IN, ESP_NOSIG)>;
				input-enable;
			};

			spim3_miso_gpio42: spim3_miso_gpio42 {
				pinmux = <ESP32_PINMUX(42, ESP_SPI3_Q_IN, ESP_NOSIG)>;
				input-enable;
			};

			spim3_miso_gpio43: spim3_miso_gpio43 {
				pinmux = <ESP32_PINMUX(43, ESP_SPI3_Q_IN, ESP_NOSIG)>;
				input-enable;
			};

			spim3_miso_gpio44: spim3_miso_gpio44 {
				pinmux = <ESP32_PINMUX(44, ESP_SPI3_Q_IN, ESP_NOSIG)>;
				input-enable;
			};

			spim3_miso_gpio45: spim3_miso_gpio45 {
				pinmux = <ESP32_PINMUX(45, ESP_SPI3_Q_IN, ESP_NOSIG)>;
				input-enable;
			};

			spim3_miso_gpio46: spim3_miso_gpio46 {
				pinmux = <ESP32_PINMUX(46, ESP_SPI3_Q_IN, ESP_NOSIG)>;
				input-enable;
			};

			/* SPIM3's MOSI pin states */
			spim3_mosi_gpio0: spim3_mosi_gpio0 {
				pinmux = <ESP32_PINMUX(0, ESP_NOSIG, ESP_SPI3_D_OUT)>;
				output-low;
			};

			spim3_mosi_gpio1: spim3_mosi_gpio1 {
				pinmux = <ESP32_PINMUX(1, ESP_NOSIG, ESP_SPI3_D_OUT)>;
				output-low;
			};

			spim3_mosi_gpio2: spim3_mosi_gpio2 {
				pinmux = <ESP32_PINMUX(2, ESP_NOSIG, ESP_SPI3_D_OUT)>;
				output-low;
			};

			spim3_mosi_gpio3: spim3_mosi_gpio3 {
				pinmux = <ESP32_PINMUX(3, ESP_NOSIG, ESP_SPI3_D_OUT)>;
				output-low;
			};

			spim3_mosi_gpio4: spim3_mosi_gpio4 {
				pinmux = <ESP32_PINMUX(4, ESP_NOSIG, ESP_SPI3_D_OUT)>;
				output-low;
			};

			spim3_mosi_gpio5: spim3_mosi_gpio5 {
				pinmux = <ESP32_PINMUX(5, ESP_NOSIG, ESP_SPI3_D_OUT)>;
				output-low;
			};

			spim3_mosi_gpio6: spim3_mosi_gpio6 {
				pinmux = <ESP32_PINMUX(6, ESP_NOSIG, ESP_SPI3_D_OUT)>;
				output-low;
			};

			spim3_mosi_gpio7: spim3_mosi_gpio7 {
				pinmux = <ESP32_PINMUX(7, ESP_NOSIG, ESP_SPI3_D_OUT)>;
				output-low;
			};

			spim3_mosi_gpio8: spim3_mosi_gpio8 {
				pinmux = <ESP32_PINMUX(8, ESP_NOSIG, ESP_SPI3_D_OUT)>;
				output-low;
			};

			spim3_mosi_gpio9: spim3_mosi_gpio9 {
				pinmux = <ESP32_PINMUX(9, ESP_NOSIG, ESP_SPI3_D_OUT)>;
				output-low;
			};

			spim3_mosi_gpio10: spim3_mosi_gpio10 {
				pinmux = <ESP32_PINMUX(10, ESP_NOSIG, ESP_SPI3_D_OUT)>;
				output-low;
			};

			spim3_mosi_gpio11: spim3_mosi_gpio11 {
				pinmux = <ESP32_PINMUX(11, ESP_NOSIG, ESP_SPI3_D_OUT)>;
				output-low;
			};

			spim3_mosi_gpio12: spim3_mosi_gpio12 {
				pinmux = <ESP32_PINMUX(12, ESP_NOSIG, ESP_SPI3_D_OUT)>;
				output-low;
			};

			spim3_mosi_gpio13: spim3_mosi_gpio13 {
				pinmux = <ESP32_PINMUX(13, ESP_NOSIG, ESP_SPI3_D_OUT)>;
				output-low;
			};

			spim3_mosi_gpio14: spim3_mosi_gpio14 {
				pinmux = <ESP32_PINMUX(14, ESP_NOSIG, ESP_SPI3_D_OUT)>;
				output-low;
			};

			spim3_mosi_gpio15: spim3_mosi_gpio15 {
				pinmux = <ESP32_PINMUX(15, ESP_NOSIG, ESP_SPI3_D_OUT)>;
				output-low;
			};

			spim3_mosi_gpio16: spim3_mosi_gpio16 {
				pinmux = <ESP32_PINMUX(16, ESP_NOSIG, ESP_SPI3_D_OUT)>;
				output-low;
			};

			spim3_mosi_gpio17: spim3_mosi_gpio17 {
				pinmux = <ESP32_PINMUX(17, ESP_NOSIG, ESP_SPI3_D_OUT)>;
				output-low;
			};

			spim3_mosi_gpio18: spim3_mosi_gpio18 {
				pinmux = <ESP32_PINMUX(18, ESP_NOSIG, ESP_SPI3_D_OUT)>;
				output-low;
			};

			spim3_mosi_gpio19: spim3_mosi_gpio19 {
				pinmux = <ESP32_PINMUX(19, ESP_NOSIG, ESP_SPI3_D_OUT)>;
				output-low;
			};

			spim3_mosi_gpio20: spim3_mosi_gpio20 {
				pinmux = <ESP32_PINMUX(20, ESP_NOSIG, ESP_SPI3_D_OUT)>;
				output-low;
			};

			spim3_mosi_gpio21: spim3_mosi_gpio21 {
				pinmux = <ESP32_PINMUX(21, ESP_NOSIG, ESP_SPI3_D_OUT)>;
				output-low;
			};

			spim3_mosi_gpio26: spim3_mosi_gpio26 {
				pinmux = <ESP32_PINMUX(26, ESP_NOSIG, ESP_SPI3_D_OUT)>;
				output-low;
			};

			spim3_mosi_gpio27: spim3_mosi_gpio27 {
				pinmux = <ESP32_PINMUX(27, ESP_NOSIG, ESP_SPI3_D_OUT)>;
				output-low;
			};

			spim3_mosi_gpio28: spim3_mosi_gpio28 {
				pinmux = <ESP32_PINMUX(28, ESP_NOSIG, ESP_SPI3_D_OUT)>;
				output-low;
			};

			spim3_mosi_gpio29: spim3_mosi_gpio29 {
				pinmux = <ESP32_PINMUX(29, ESP_NOSIG, ESP_SPI3_D_OUT)>;
				output-low;
			};

			spim3_mosi_gpio30: spim3_mosi_gpio30 {
				pinmux = <ESP32_PINMUX(30, ESP_NOSIG, ESP_SPI3_D_OUT)>;
				output-low;
			};

			spim3_mosi_gpio31: spim3_mosi_gpio31 {
				pinmux = <ESP32_PINMUX(31, ESP_NOSIG, ESP_SPI3_D_OUT)>;
				output-low;
			};

			spim3_mosi_gpio32: spim3_mosi_gpio32 {
				pinmux = <ESP32_PINMUX(32, ESP_NOSIG, ESP_SPI3_D_OUT)>;
				output-low;
			};

			spim3_mosi_gpio33: spim3_mosi_gpio33 {
				pinmux = <ESP32_PINMUX(33, ESP_NOSIG, ESP_SPI3_D_OUT)>;
				output-low;
			};

			spim3_mosi_gpio34: spim3_mosi_gpio34 {
				pinmux = <ESP32_PINMUX(34, ESP_NOSIG, ESP_SPI3_D_OUT)>;
				output-low;
			};

			spim3_mosi_gpio35: spim3_mosi_gpio35 {
				pinmux = <ESP32_PINMUX(35, ESP_NOSIG, ESP_SPI3_D_OUT)>;
				output-low;
			};

			spim3_mosi_gpio36: spim3_mosi_gpio36 {
				pinmux = <ESP32_PINMUX(36, ESP_NOSIG, ESP_SPI3_D_OUT)>;
				output-low;
			};

			spim3_mosi_gpio37: spim3_mosi_gpio37 {
				pinmux = <ESP32_PINMUX(37, ESP_NOSIG, ESP_SPI3_D_OUT)>;
				output-low;
			};

			spim3_mosi_gpio38: spim3_mosi_gpio38 {
				pinmux = <ESP32_PINMUX(38, ESP_NOSIG, ESP_SPI3_D_OUT)>;
				output-low;
			};

			spim3_mosi_gpio39: spim3_mosi_gpio39 {
				pinmux = <ESP32_PINMUX(39, ESP_NOSIG, ESP_SPI3_D_OUT)>;
				output-low;
			};

			spim3_mosi_gpio40: spim3_mosi_gpio40 {
				pinmux = <ESP32_PINMUX(40, ESP_NOSIG, ESP_SPI3_D_OUT)>;
				output-low;
			};

			spim3_mosi_gpio41: spim3_mosi_gpio41 {
				pinmux = <ESP32_PINMUX(41, ESP_NOSIG, ESP_SPI3_D_OUT)>;
				output-low;
			};

			spim3_mosi_gpio42: spim3_mosi_gpio42 {
				pinmux = <ESP32_PINMUX(42, ESP_NOSIG, ESP_SPI3_D_OUT)>;
				output-low;
			};

			spim3_mosi_gpio43: spim3_mosi_gpio43 {
				pinmux = <ESP32_PINMUX(43, ESP_NOSIG, ESP_SPI3_D_OUT)>;
				output-low;
			};

			spim3_mosi_gpio44: spim3_mosi_gpio44 {
				pinmux = <ESP32_PINMUX(44, ESP_NOSIG, ESP_SPI3_D_OUT)>;
				output-low;
			};

			spim3_mosi_gpio45: spim3_mosi_gpio45 {
				pinmux = <ESP32_PINMUX(45, ESP_NOSIG, ESP_SPI3_D_OUT)>;
				output-low;
			};

			/* SPIM3's SCLK pin states */
			spim3_sclk_gpio0: spim3_sclk_gpio0 {
				pinmux = <ESP32_PINMUX(0, ESP_NOSIG, ESP_SPI3_CLK_OUT_MUX)>;
				output-enable;
			};

			spim3_sclk_gpio1: spim3_sclk_gpio1 {
				pinmux = <ESP32_PINMUX(1, ESP_NOSIG, ESP_SPI3_CLK_OUT_MUX)>;
				output-enable;
			};

			spim3_sclk_gpio2: spim3_sclk_gpio2 {
				pinmux = <ESP32_PINMUX(2, ESP_NOSIG, ESP_SPI3_CLK_OUT_MUX)>;
				output-enable;
			};

			spim3_sclk_gpio3: spim3_sclk_gpio3 {
				pinmux = <ESP32_PINMUX(3, ESP_NOSIG, ESP_SPI3_CLK_OUT_MUX)>;
				output-enable;
			};

			spim3_sclk_gpio4: spim3_sclk_gpio4 {
				pinmux = <ESP32_PINMUX(4, ESP_NOSIG, ESP_SPI3_CLK_OUT_MUX)>;
				output-enable;
			};

			spim3_sclk_gpio5: spim3_sclk_gpio5 {
				pinmux = <ESP32_PINMUX(5, ESP_NOSIG, ESP_SPI3_CLK_OUT_MUX)>;
				output-enable;
			};

			spim3_sclk_gpio6: spim3_sclk_gpio6 {
				pinmux = <ESP32_PINMUX(6, ESP_NOSIG, ESP_SPI3_CLK_OUT_MUX)>;
				output-enable;
			};

			spim3_sclk_gpio7: spim3_sclk_gpio7 {
				pinmux = <ESP32_PINMUX(7, ESP_NOSIG, ESP_SPI3_CLK_OUT_MUX)>;
				output-enable;
			};

			spim3_sclk_gpio8: spim3_sclk_gpio8 {
				pinmux = <ESP32_PINMUX(8, ESP_NOSIG, ESP_SPI3_CLK_OUT_MUX)>;
				output-enable;
			};

			spim3_sclk_gpio9: spim3_sclk_gpio9 {
				pinmux = <ESP32_PINMUX(9, ESP_NOSIG, ESP_SPI3_CLK_OUT_MUX)>;
				output-enable;
			};

			spim3_sclk_gpio10: spim3_sclk_gpio10 {
				pinmux = <ESP32_PINMUX(10, ESP_NOSIG, ESP_SPI3_CLK_OUT_MUX)>;
				output-enable;
			};

			spim3_sclk_gpio11: spim3_sclk_gpio11 {
				pinmux = <ESP32_PINMUX(11, ESP_NOSIG, ESP_SPI3_CLK_OUT_MUX)>;
				output-enable;
			};

			spim3_sclk_gpio12: spim3_sclk_gpio12 {
				pinmux = <ESP32_PINMUX(12, ESP_NOSIG, ESP_SPI3_CLK_OUT_MUX)>;
				output-enable;
			};

			spim3_sclk_gpio13: spim3_sclk_gpio13 {
				pinmux = <ESP32_PINMUX(13, ESP_NOSIG, ESP_SPI3_CLK_OUT_MUX)>;
				output-enable;
			};

			spim3_sclk_gpio14: spim3_sclk_gpio14 {
				pinmux = <ESP32_PINMUX(14, ESP_NOSIG, ESP_SPI3_CLK_OUT_MUX)>;
				output-enable;
			};

			spim3_sclk_gpio15: spim3_sclk_gpio15 {
				pinmux = <ESP32_PINMUX(15, ESP_NOSIG, ESP_SPI3_CLK_OUT_MUX)>;
				output-enable;
			};

			spim3_sclk_gpio16: spim3_sclk_gpio16 {
				pinmux = <ESP32_PINMUX(16, ESP_NOSIG, ESP_SPI3_CLK_OUT_MUX)>;
				output-enable;
			};

			spim3_sclk_gpio17: spim3_sclk_gpio17 {
				pinmux = <ESP32_PINMUX(17, ESP_NOSIG, ESP_SPI3_CLK_OUT_MUX)>;
				output-enable;
			};

			spim3_sclk_gpio18: spim3_sclk_gpio18 {
				pinmux = <ESP32_PINMUX(18, ESP_NOSIG, ESP_SPI3_CLK_OUT_MUX)>;
				output-enable;
			};

			spim3_sclk_gpio19: spim3_sclk_gpio19 {
				pinmux = <ESP32_PINMUX(19, ESP_NOSIG, ESP_SPI3_CLK_OUT_MUX)>;
				output-enable;
			};

			spim3_sclk_gpio20: spim3_sclk_gpio20 {
				pinmux = <ESP32_PINMUX(20, ESP_NOSIG, ESP_SPI3_CLK_OUT_MUX)>;
				output-enable;
			};

			spim3_sclk_gpio21: spim3_sclk_gpio21 {
				pinmux = <ESP32_PINMUX(21, ESP_NOSIG, ESP_SPI3_CLK_OUT_MUX)>;
				output-enable;
			};

			spim3_sclk_gpio26: spim3_sclk_gpio26 {
				pinmux = <ESP32_PINMUX(26, ESP_NOSIG, ESP_SPI3_CLK_OUT_MUX)>;
				output-enable;
			};

			spim3_sclk_gpio27: spim3_sclk_gpio27 {
				pinmux = <ESP32_PINMUX(27, ESP_NOSIG, ESP_SPI3_CLK_OUT_MUX)>;
				output-enable;
			};

			spim3_sclk_gpio28: spim3_sclk_gpio28 {
				pinmux = <ESP32_PINMUX(28, ESP_NOSIG, ESP_SPI3_CLK_OUT_MUX)>;
				output-enable;
			};

			spim3_sclk_gpio29: spim3_sclk_gpio29 {
				pinmux = <ESP32_PINMUX(29, ESP_NOSIG, ESP_SPI3_CLK_OUT_MUX)>;
				output-enable;
			};

			spim3_sclk_gpio30: spim3_sclk_gpio30 {
				pinmux = <ESP32_PINMUX(30, ESP_NOSIG, ESP_SPI3_CLK_OUT_MUX)>;
				output-enable;
			};

			spim3_sclk_gpio31: spim3_sclk_gpio31 {
				pinmux = <ESP32_PINMUX(31, ESP_NOSIG, ESP_SPI3_CLK_OUT_MUX)>;
				output-enable;
			};

			spim3_sclk_gpio32: spim3_sclk_gpio32 {
				pinmux = <ESP32_PINMUX(32, ESP_NOSIG, ESP_SPI3_CLK_OUT_MUX)>;
				output-enable;
			};

			spim3_sclk_gpio33: spim3_sclk_gpio33 {
				pinmux = <ESP32_PINMUX(33, ESP_NOSIG, ESP_SPI3_CLK_OUT_MUX)>;
				output-enable;
			};

			spim3_sclk_gpio34: spim3_sclk_gpio34 {
				pinmux = <ESP32_PINMUX(34, ESP_NOSIG, ESP_SPI3_CLK_OUT_MUX)>;
				output-enable;
			};

			spim3_sclk_gpio35: spim3_sclk_gpio35 {
				pinmux = <ESP32_PINMUX(35, ESP_NOSIG, ESP_SPI3_CLK_OUT_MUX)>;
				output-enable;
			};

			spim3_sclk_gpio36: spim3_sclk_gpio36 {
				pinmux = <ESP32_PINMUX(36, ESP_NOSIG, ESP_SPI3_CLK_OUT_MUX)>;
				output-enable;
			};

			spim3_sclk_gpio37: spim3_sclk_gpio37 {
				pinmux = <ESP32_PINMUX(37, ESP_NOSIG, ESP_SPI3_CLK_OUT_MUX)>;
				output-enable;
			};

			spim3_sclk_gpio38: spim3_sclk_gpio38 {
				pinmux = <ESP32_PINMUX(38, ESP_NOSIG, ESP_SPI3_CLK_OUT_MUX)>;
				output-enable;
			};

			spim3_sclk_gpio39: spim3_sclk_gpio39 {
				pinmux = <ESP32_PINMUX(39, ESP_NOSIG, ESP_SPI3_CLK_OUT_MUX)>;
				output-enable;
			};

			spim3_sclk_gpio40: spim3_sclk_gpio40 {
				pinmux = <ESP32_PINMUX(40, ESP_NOSIG, ESP_SPI3_CLK_OUT_MUX)>;
				output-enable;
			};

			spim3_sclk_gpio41: spim3_sclk_gpio41 {
				pinmux = <ESP32_PINMUX(41, ESP_NOSIG, ESP_SPI3_CLK_OUT_MUX)>;
				output-enable;
			};

			spim3_sclk_gpio42: spim3_sclk_gpio42 {
				pinmux = <ESP32_PINMUX(42, ESP_NOSIG, ESP_SPI3_CLK_OUT_MUX)>;
				output-enable;
			};

			spim3_sclk_gpio43: spim3_sclk_gpio43 {
				pinmux = <ESP32_PINMUX(43, ESP_NOSIG, ESP_SPI3_CLK_OUT_MUX)>;
				output-enable;
			};

			spim3_sclk_gpio44: spim3_sclk_gpio44 {
				pinmux = <ESP32_PINMUX(44, ESP_NOSIG, ESP_SPI3_CLK_OUT_MUX)>;
				output-enable;
			};

			spim3_sclk_gpio45: spim3_sclk_gpio45 {
				pinmux = <ESP32_PINMUX(45, ESP_NOSIG, ESP_SPI3_CLK_OUT_MUX)>;
				output-enable;
			};

			/* UART0's RX pin states */
			uart0_rx_gpio0: uart0_rx_gpio0 {
				pinmux = <ESP32_PINMUX(0, ESP_U0RXD_IN, ESP_NOSIG)>;
				bias-pull-up;
				input-enable;
			};

			uart0_rx_gpio1: uart0_rx_gpio1 {
				pinmux = <ESP32_PINMUX(1, ESP_U0RXD_IN, ESP_NOSIG)>;
				bias-pull-up;
				input-enable;
			};

			uart0_rx_gpio2: uart0_rx_gpio2 {
				pinmux = <ESP32_PINMUX(2, ESP_U0RXD_IN, ESP_NOSIG)>;
				bias-pull-up;
				input-enable;
			};

			uart0_rx_gpio3: uart0_rx_gpio3 {
				pinmux = <ESP32_PINMUX(3, ESP_U0RXD_IN, ESP_NOSIG)>;
				bias-pull-up;
				input-enable;
			};

			uart0_rx_gpio4: uart0_rx_gpio4 {
				pinmux = <ESP32_PINMUX(4, ESP_U0RXD_IN, ESP_NOSIG)>;
				bias-pull-up;
				input-enable;
			};

			uart0_rx_gpio5: uart0_rx_gpio5 {
				pinmux = <ESP32_PINMUX(5, ESP_U0RXD_IN, ESP_NOSIG)>;
				bias-pull-up;
				input-enable;
			};

			uart0_rx_gpio6: uart0_rx_gpio6 {
				pinmux = <ESP32_PINMUX(6, ESP_U0RXD_IN, ESP_NOSIG)>;
				bias-pull-up;
				input-enable;
			};

			uart0_rx_gpio7: uart0_rx_gpio7 {
				pinmux = <ESP32_PINMUX(7, ESP_U0RXD_IN, ESP_NOSIG)>;
				bias-pull-up;
				input-enable;
			};

			uart0_rx_gpio8: uart0_rx_gpio8 {
				pinmux = <ESP32_PINMUX(8, ESP_U0RXD_IN, ESP_NOSIG)>;
				bias-pull-up;
				input-enable;
			};

			uart0_rx_gpio9: uart0_rx_gpio9 {
				pinmux = <ESP32_PINMUX(9, ESP_U0RXD_IN, ESP_NOSIG)>;
				bias-pull-up;
				input-enable;
			};

			uart0_rx_gpio10: uart0_rx_gpio10 {
				pinmux = <ESP32_PINMUX(10, ESP_U0RXD_IN, ESP_NOSIG)>;
				bias-pull-up;
				input-enable;
			};

			uart0_rx_gpio11: uart0_rx_gpio11 {
				pinmux = <ESP32_PINMUX(11, ESP_U0RXD_IN, ESP_NOSIG)>;
				bias-pull-up;
				input-enable;
			};

			uart0_rx_gpio12: uart0_rx_gpio12 {
				pinmux = <ESP32_PINMUX(12, ESP_U0RXD_IN, ESP_NOSIG)>;
				bias-pull-up;
				input-enable;
			};

			uart0_rx_gpio13: uart0_rx_gpio13 {
				pinmux = <ESP32_PINMUX(13, ESP_U0RXD_IN, ESP_NOSIG)>;
				bias-pull-up;
				input-enable;
			};

			uart0_rx_gpio14: uart0_rx_gpio14 {
				pinmux = <ESP32_PINMUX(14, ESP_U0RXD_IN, ESP_NOSIG)>;
				bias-pull-up;
				input-enable;
			};

			uart0_rx_gpio15: uart0_rx_gpio15 {
				pinmux = <ESP32_PINMUX(15, ESP_U0RXD_IN, ESP_NOSIG)>;
				bias-pull-up;
				input-enable;
			};

			uart0_rx_gpio16: uart0_rx_gpio16 {
				pinmux = <ESP32_PINMUX(16, ESP_U0RXD_IN, ESP_NOSIG)>;
				bias-pull-up;
				input-enable;
			};

			uart0_rx_gpio17: uart0_rx_gpio17 {
				pinmux = <ESP32_PINMUX(17, ESP_U0RXD_IN, ESP_NOSIG)>;
				bias-pull-up;
				input-enable;
			};

			uart0_rx_gpio18: uart0_rx_gpio18 {
				pinmux = <ESP32_PINMUX(18, ESP_U0RXD_IN, ESP_NOSIG)>;
				bias-pull-up;
				input-enable;
			};

			uart0_rx_gpio19: uart0_rx_gpio19 {
				pinmux = <ESP32_PINMUX(19, ESP_U0RXD_IN, ESP_NOSIG)>;
				bias-pull-up;
				input-enable;
			};

			uart0_rx_gpio20: uart0_rx_gpio20 {
				pinmux = <ESP32_PINMUX(20, ESP_U0RXD_IN, ESP_NOSIG)>;
				bias-pull-up;
				input-enable;
			};

			uart0_rx_gpio21: uart0_rx_gpio21 {
				pinmux = <ESP32_PINMUX(21, ESP_U0RXD_IN, ESP_NOSIG)>;
				bias-pull-up;
				input-enable;
			};

			uart0_rx_gpio26: uart0_rx_gpio26 {
				pinmux = <ESP32_PINMUX(26, ESP_U0RXD_IN, ESP_NOSIG)>;
				bias-pull-up;
				input-enable;
			};

			uart0_rx_gpio27: uart0_rx_gpio27 {
				pinmux = <ESP32_PINMUX(27, ESP_U0RXD_IN, ESP_NOSIG)>;
				bias-pull-up;
				input-enable;
			};

			uart0_rx_gpio28: uart0_rx_gpio28 {
				pinmux = <ESP32_PINMUX(28, ESP_U0RXD_IN, ESP_NOSIG)>;
				bias-pull-up;
				input-enable;
			};

			uart0_rx_gpio29: uart0_rx_gpio29 {
				pinmux = <ESP32_PINMUX(29, ESP_U0RXD_IN, ESP_NOSIG)>;
				bias-pull-up;
				input-enable;
			};

			uart0_rx_gpio30: uart0_rx_gpio30 {
				pinmux = <ESP32_PINMUX(30, ESP_U0RXD_IN, ESP_NOSIG)>;
				bias-pull-up;
				input-enable;
			};

			uart0_rx_gpio31: uart0_rx_gpio31 {
				pinmux = <ESP32_PINMUX(31, ESP_U0RXD_IN, ESP_NOSIG)>;
				bias-pull-up;
				input-enable;
			};

			uart0_rx_gpio32: uart0_rx_gpio32 {
				pinmux = <ESP32_PINMUX(32, ESP_U0RXD_IN, ESP_NOSIG)>;
				bias-pull-up;
				input-enable;
			};

			uart0_rx_gpio33: uart0_rx_gpio33 {
				pinmux = <ESP32_PINMUX(33, ESP_U0RXD_IN, ESP_NOSIG)>;
				bias-pull-up;
				input-enable;
			};

			uart0_rx_gpio34: uart0_rx_gpio34 {
				pinmux = <ESP32_PINMUX(34, ESP_U0RXD_IN, ESP_NOSIG)>;
				bias-pull-up;
				input-enable;
			};

			uart0_rx_gpio35: uart0_rx_gpio35 {
				pinmux = <ESP32_PINMUX(35, ESP_U0RXD_IN, ESP_NOSIG)>;
				bias-pull-up;
				input-enable;
			};

			uart0_rx_gpio36: uart0_rx_gpio36 {
				pinmux = <ESP32_PINMUX(36, ESP_U0RXD_IN, ESP_NOSIG)>;
				bias-pull-up;
				input-enable;
			};

			uart0_rx_gpio37: uart0_rx_gpio37 {
				pinmux = <ESP32_PINMUX(37, ESP_U0RXD_IN, ESP_NOSIG)>;
				bias-pull-up;
				input-enable;
			};

			uart0_rx_gpio38: uart0_rx_gpio38 {
				pinmux = <ESP32_PINMUX(38, ESP_U0RXD_IN, ESP_NOSIG)>;
				bias-pull-up;
				input-enable;
			};

			uart0_rx_gpio39: uart0_rx_gpio39 {
				pinmux = <ESP32_PINMUX(39, ESP_U0RXD_IN, ESP_NOSIG)>;
				bias-pull-up;
				input-enable;
			};

			uart0_rx_gpio40: uart0_rx_gpio40 {
				pinmux = <ESP32_PINMUX(40, ESP_U0RXD_IN, ESP_NOSIG)>;
				bias-pull-up;
				input-enable;
			};

			uart0_rx_gpio41: uart0_rx_gpio41 {
				pinmux = <ESP32_PINMUX(41, ESP_U0RXD_IN, ESP_NOSIG)>;
				bias-pull-up;
				input-enable;
			};

			uart0_rx_gpio42: uart0_rx_gpio42 {
				pinmux = <ESP32_PINMUX(42, ESP_U0RXD_IN, ESP_NOSIG)>;
				bias-pull-up;
				input-enable;
			};

			uart0_rx_gpio43: uart0_rx_gpio43 {
				pinmux = <ESP32_PINMUX(43, ESP_U0RXD_IN, ESP_NOSIG)>;
				bias-pull-up;
				input-enable;
			};

			uart0_rx_gpio44: uart0_rx_gpio44 {
				pinmux = <ESP32_PINMUX(44, ESP_U0RXD_IN, ESP_NOSIG)>;
				bias-pull-up;
				input-enable;
			};

			uart0_rx_gpio45: uart0_rx_gpio45 {
				pinmux = <ESP32_PINMUX(45, ESP_U0RXD_IN, ESP_NOSIG)>;
				bias-pull-up;
				input-enable;
			};

			uart0_rx_gpio46: uart0_rx_gpio46 {
				pinmux = <ESP32_PINMUX(46, ESP_U0RXD_IN, ESP_NOSIG)>;
				input-enable;
			};

			/* UART0's TX pin states */
			uart0_tx_gpio0: uart0_tx_gpio0 {
				pinmux = <ESP32_PINMUX(0, ESP_NOSIG, ESP_U0TXD_OUT)>;
				output-enable;
			};

			uart0_tx_gpio1: uart0_tx_gpio1 {
				pinmux = <ESP32_PINMUX(1, ESP_NOSIG, ESP_U0TXD_OUT)>;
				output-enable;
			};

			uart0_tx_gpio2: uart0_tx_gpio2 {
				pinmux = <ESP32_PINMUX(2, ESP_NOSIG, ESP_U0TXD_OUT)>;
				output-enable;
			};

			uart0_tx_gpio3: uart0_tx_gpio3 {
				pinmux = <ESP32_PINMUX(3, ESP_NOSIG, ESP_U0TXD_OUT)>;
				output-enable;
			};

			uart0_tx_gpio4: uart0_tx_gpio4 {
				pinmux = <ESP32_PINMUX(4, ESP_NOSIG, ESP_U0TXD_OUT)>;
				output-enable;
			};

			uart0_tx_gpio5: uart0_tx_gpio5 {
				pinmux = <ESP32_PINMUX(5, ESP_NOSIG, ESP_U0TXD_OUT)>;
				output-enable;
			};

			uart0_tx_gpio6: uart0_tx_gpio6 {
				pinmux = <ESP32_PINMUX(6, ESP_NOSIG, ESP_U0TXD_OUT)>;
				output-enable;
			};

			uart0_tx_gpio7: uart0_tx_gpio7 {
				pinmux = <ESP32_PINMUX(7, ESP_NOSIG, ESP_U0TXD_OUT)>;
				output-enable;
			};

			uart0_tx_gpio8: uart0_tx_gpio8 {
				pinmux = <ESP32_PINMUX(8, ESP_NOSIG, ESP_U0TXD_OUT)>;
				output-enable;
			};

			uart0_tx_gpio9: uart0_tx_gpio9 {
				pinmux = <ESP32_PINMUX(9, ESP_NOSIG, ESP_U0TXD_OUT)>;
				output-enable;
			};

			uart0_tx_gpio10: uart0_tx_gpio10 {
				pinmux = <ESP32_PINMUX(10, ESP_NOSIG, ESP_U0TXD_OUT)>;
				output-enable;
			};

			uart0_tx_gpio11: uart0_tx_gpio11 {
				pinmux = <ESP32_PINMUX(11, ESP_NOSIG, ESP_U0TXD_OUT)>;
				output-enable;
			};

			uart0_tx_gpio12: uart0_tx_gpio12 {
				pinmux = <ESP32_PINMUX(12, ESP_NOSIG, ESP_U0TXD_OUT)>;
				output-enable;
			};

			uart0_tx_gpio13: uart0_tx_gpio13 {
				pinmux = <ESP32_PINMUX(13, ESP_NOSIG, ESP_U0TXD_OUT)>;
				output-enable;
			};

			uart0_tx_gpio14: uart0_tx_gpio14 {
				pinmux = <ESP32_PINMUX(14, ESP_NOSIG, ESP_U0TXD_OUT)>;
				output-enable;
			};

			uart0_tx_gpio15: uart0_tx_gpio15 {
				pinmux = <ESP32_PINMUX(15, ESP_NOSIG, ESP_U0TXD_OUT)>;
				output-enable;
			};

			uart0_tx_gpio16: uart0_tx_gpio16 {
				pinmux = <ESP32_PINMUX(16, ESP_NOSIG, ESP_U0TXD_OUT)>;
				output-enable;
			};

			uart0_tx_gpio17: uart0_tx_gpio17 {
				pinmux = <ESP32_PINMUX(17, ESP_NOSIG, ESP_U0TXD_OUT)>;
				output-enable;
			};

			uart0_tx_gpio18: uart0_tx_gpio18 {
				pinmux = <ESP32_PINMUX(18, ESP_NOSIG, ESP_U0TXD_OUT)>;
				output-enable;
			};

			uart0_tx_gpio19: uart0_tx_gpio19 {
				pinmux = <ESP32_PINMUX(19, ESP_NOSIG, ESP_U0TXD_OUT)>;
				output-enable;
			};

			uart0_tx_gpio20: uart0_tx_gpio20 {
				pinmux = <ESP32_PINMUX(20, ESP_NOSIG, ESP_U0TXD_OUT)>;
				output-enable;
			};

			uart0_tx_gpio21: uart0_tx_gpio21 {
				pinmux = <ESP32_PINMUX(21, ESP_NOSIG, ESP_U0TXD_OUT)>;
				output-enable;
			};

			uart0_tx_gpio26: uart0_tx_gpio26 {
				pinmux = <ESP32_PINMUX(26, ESP_NOSIG, ESP_U0TXD_OUT)>;
				output-enable;
			};

			uart0_tx_gpio27: uart0_tx_gpio27 {
				pinmux = <ESP32_PINMUX(27, ESP_NOSIG, ESP_U0TXD_OUT)>;
				output-enable;
			};

			uart0_tx_gpio28: uart0_tx_gpio28 {
				pinmux = <ESP32_PINMUX(28, ESP_NOSIG, ESP_U0TXD_OUT)>;
				output-enable;
			};

			uart0_tx_gpio29: uart0_tx_gpio29 {
				pinmux = <ESP32_PINMUX(29, ESP_NOSIG, ESP_U0TXD_OUT)>;
				output-enable;
			};

			uart0_tx_gpio30: uart0_tx_gpio30 {
				pinmux = <ESP32_PINMUX(30, ESP_NOSIG, ESP_U0TXD_OUT)>;
				output-enable;
			};

			uart0_tx_gpio31: uart0_tx_gpio31 {
				pinmux = <ESP32_PINMUX(31, ESP_NOSIG, ESP_U0TXD_OUT)>;
				output-enable;
			};

			uart0_tx_gpio32: uart0_tx_gpio32 {
				pinmux = <ESP32_PINMUX(32, ESP_NOSIG, ESP_U0TXD_OUT)>;
				output-enable;
			};

			uart0_tx_gpio33: uart0_tx_gpio33 {
				pinmux = <ESP32_PINMUX(33, ESP_NOSIG, ESP_U0TXD_OUT)>;
				output-enable;
			};

			uart0_tx_gpio34: uart0_tx_gpio34 {
				pinmux = <ESP32_PINMUX(34, ESP_NOSIG, ESP_U0TXD_OUT)>;
				output-enable;
			};

			uart0_tx_gpio35: uart0_tx_gpio35 {
				pinmux = <ESP32_PINMUX(35, ESP_NOSIG, ESP_U0TXD_OUT)>;
				output-enable;
			};

			uart0_tx_gpio36: uart0_tx_gpio36 {
				pinmux = <ESP32_PINMUX(36, ESP_NOSIG, ESP_U0TXD_OUT)>;
				output-enable;
			};

			uart0_tx_gpio37: uart0_tx_gpio37 {
				pinmux = <ESP32_PINMUX(37, ESP_NOSIG, ESP_U0TXD_OUT)>;
				output-enable;
			};

			uart0_tx_gpio38: uart0_tx_gpio38 {
				pinmux = <ESP32_PINMUX(38, ESP_NOSIG, ESP_U0TXD_OUT)>;
				output-enable;
			};

			uart0_tx_gpio39: uart0_tx_gpio39 {
				pinmux = <ESP32_PINMUX(39, ESP_NOSIG, ESP_U0TXD_OUT)>;
				output-enable;
			};

			uart0_tx_gpio40: uart0_tx_gpio40 {
				pinmux = <ESP32_PINMUX(40, ESP_NOSIG, ESP_U0TXD_OUT)>;
				output-enable;
			};

			uart0_tx_gpio41: uart0_tx_gpio41 {
				pinmux = <ESP32_PINMUX(41, ESP_NOSIG, ESP_U0TXD_OUT)>;
				output-enable;
			};

			uart0_tx_gpio42: uart0_tx_gpio42 {
				pinmux = <ESP32_PINMUX(42, ESP_NOSIG, ESP_U0TXD_OUT)>;
				output-enable;
			};

			uart0_tx_gpio43: uart0_tx_gpio43 {
				pinmux = <ESP32_PINMUX(43, ESP_NOSIG, ESP_U0TXD_OUT)>;
				output-enable;
			};

			uart0_tx_gpio44: uart0_tx_gpio44 {
				pinmux = <ESP32_PINMUX(44, ESP_NOSIG, ESP_U0TXD_OUT)>;
				output-enable;
			};

			uart0_tx_gpio45: uart0_tx_gpio45 {
				pinmux = <ESP32_PINMUX(45, ESP_NOSIG, ESP_U0TXD_OUT)>;
				output-enable;
			};

		};
	};
};
